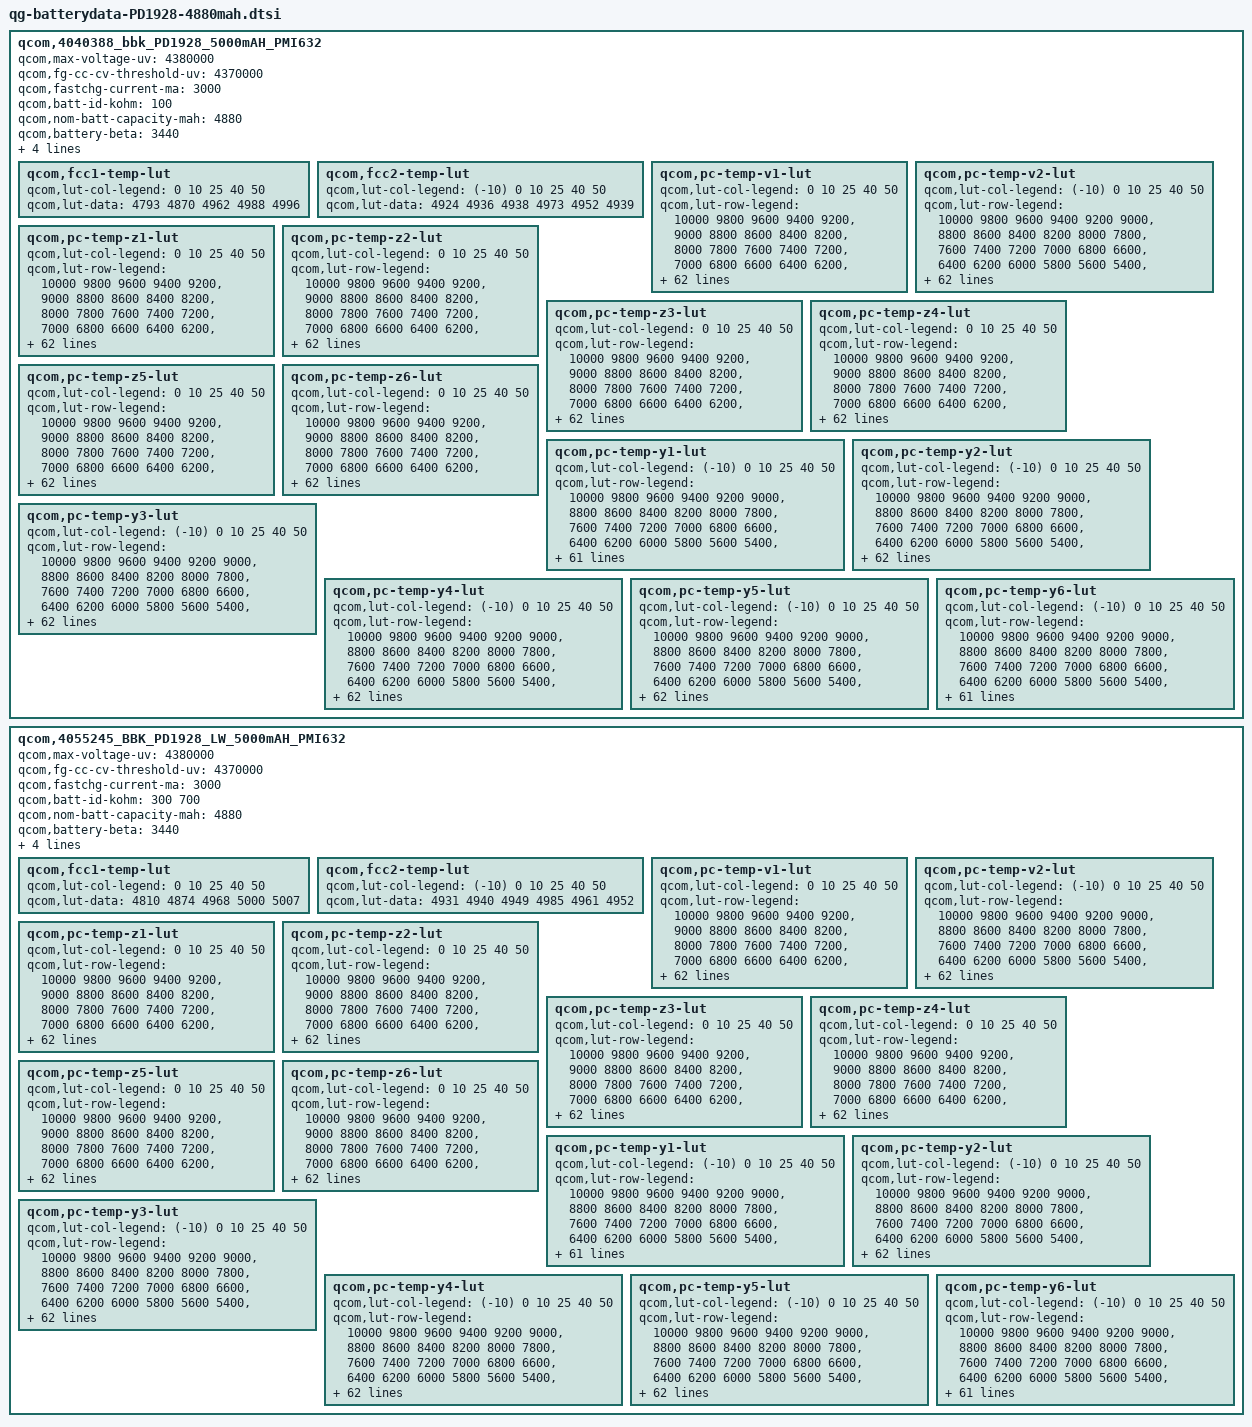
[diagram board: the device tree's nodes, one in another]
/*
 * Copyright (c) 2018, The Linux Foundation. All rights reserved.
 *
 * This program is free software; you can redistribute it and/or modify
 * it under the terms of the GNU General Public License version 2 and
 * only version 2 as published by the Free Software Foundation.
 *
 * This program is distributed in the hope that it will be useful,
 * but WITHOUT ANY WARRANTY; without even the implied warranty of
 * MERCHANTABILITY or FITNESS FOR A PARTICULAR PURPOSE.  See the
 * GNU General Public License for more details.
 */

qcom,4040388_bbk_PD1928_5000mAH_PMI632 {
    /* 4040388_bbk_PD1928_5000mAH_PMI632_averaged_MasterSlave_Jun3th2019 */
    qcom,max-voltage-uv = <4380000>;
    qcom,fg-cc-cv-threshold-uv = <4370000>;
    qcom,fastchg-current-ma = <3000>;
    qcom,batt-id-kohm = <100>;
    qcom,nom-batt-capacity-mah = <4880>;/*min value*/
    qcom,battery-beta = <3440>;
    qcom,battery-therm-kohm = <10>;
    qcom,battery-type = "vivo_PD1928_batterydata:batid(100)";
    qcom,qg-batt-profile-ver = <100>;

	qcom,fcc1-temp-lut {
		qcom,lut-col-legend = <0 10 25 40 50>;
		qcom,lut-data = <4793 4870 4962 4988 4996>;
	};

	qcom,fcc2-temp-lut {
		qcom,lut-col-legend = <(-10) 0 10 25 40 50>;
		qcom,lut-data = <4924 4936 4938 4973 4952 4939>;
	};

	qcom,pc-temp-v1-lut {
		qcom,lut-col-legend = <0 10 25 40 50>;
		qcom,lut-row-legend = <10000 9800 9600 9400 9200>,
			<9000 8800 8600 8400 8200>,
			<8000 7800 7600 7400 7200>,
			<7000 6800 6600 6400 6200>,
			<6000 5800 5600 5400 5200>,
			<5000 4800 4600 4400 4200>,
			<4000 3800 3600 3400 3200>,
			<3000 2800 2600 2400 2200>,
			<2000 1800 1600 1400 1200>,
			<1000 900 800 700 600>,
			<500 400 300 200 100>,
			<0>;
		qcom,lut-data = <43511 43601 43661 43681 43684>,
			<43280 43384 43430 43447 43452>,
			<43030 43152 43198 43214 43222>,
			<42784 42910 42962 42981 42992>,
			<42549 42671 42724 42750 42764>,
			<42320 42434 42490 42520 42536>,
			<42100 42201 42258 42290 42307>,
			<41888 41976 42030 42062 42078>,
			<41683 41758 41804 41836 41854>,
			<41480 41545 41581 41612 41632>,
			<41280 41339 41366 41392 41414>,
			<41084 41139 41162 41178 41198>,
			<40893 40940 40961 40968 40986>,
			<40703 40745 40754 40765 40782>,
			<40492 40547 40543 40566 40583>,
			<40253 40335 40343 40374 40392>,
			<40041 40124 40150 40188 40208>,
			<39890 39952 39971 40011 40032>,
			<39763 39823 39822 39848 39866>,
			<39628 39689 39693 39703 39715>,
			<39484 39494 39537 39543 39551>,
			<39330 39256 39318 39336 39346>,
			<39152 39064 39096 39120 39131>,
			<38948 38920 38929 38946 38955>,
			<38796 38799 38790 38798 38805>,
			<38709 38694 38669 38670 38675>,
			<38641 38603 38564 38559 38561>,
			<38574 38522 38470 38462 38460>,
			<38510 38449 38385 38371 38369>,
			<38451 38383 38308 38288 38285>,
			<38397 38326 38242 38214 38209>,
			<38348 38274 38182 38148 38137>,
			<38304 38227 38131 38089 38072>,
			<38267 38186 38086 38038 38014>,
			<38233 38148 38050 37995 37965>,
			<38202 38114 38012 37950 37912>,
			<38174 38086 37976 37899 37850>,
			<38138 38052 37936 37843 37782>,
			<38073 37994 37877 37776 37707>,
			<37983 37908 37793 37696 37624>,
			<37886 37809 37696 37604 37531>,
			<37774 37691 37587 37495 37420>,
			<37640 37555 37461 37368 37292>,
			<37476 37395 37307 37213 37137>,
			<37348 37254 37170 37079 37008>,
			<37257 37157 37076 36990 36926>,
			<37222 37129 37047 36963 36904>,
			<37195 37107 37028 36945 36883>,
			<37167 37089 37009 36924 36860>,
			<37103 37031 36942 36839 36750>,
			<36844 36751 36646 36524 36421>,
			<36398 36311 36210 36086 35982>,
			<35829 35747 35644 35521 35413>,
			<35061 34980 34876 34754 34639>,
			<33849 33784 33685 33567 33442>,
			<30000 30000 30000 30000 30000>;
	};

	qcom,pc-temp-v2-lut {
		qcom,lut-col-legend = <(-10) 0 10 25 40 50>;
		qcom,lut-row-legend = <10000 9800 9600 9400 9200 9000>,
			<8800 8600 8400 8200 8000 7800>,
			<7600 7400 7200 7000 6800 6600>,
			<6400 6200 6000 5800 5600 5400>,
			<5200 5000 4800 4600 4400 4200>,
			<4000 3800 3600 3400 3200 3000>,
			<2800 2600 2400 2200 2000 1800>,
			<1600 1400 1200 1000 900 800>,
			<700 600 500 400 300 200>,
			<100 0>;
		qcom,lut-data = <43685 43690 43655 43665 43590 43575>,
			<43310 43365 43368 43386 43326 43314>,
			<42966 43063 43097 43120 43070 43062>,
			<42658 42788 42843 42869 42825 42819>,
			<42384 42539 42605 42633 42590 42585>,
			<42123 42299 42375 42401 42359 42355>,
			<41852 42062 42144 42168 42128 42125>,
			<41592 41829 41917 41938 41900 41897>,
			<41386 41601 41695 41713 41675 41673>,
			<41236 41375 41475 41491 41454 41452>,
			<41079 41162 41261 41273 41236 41235>,
			<40871 40983 41060 41061 41022 41022>,
			<40624 40817 40866 40853 40813 40814>,
			<40340 40614 40658 40647 40611 40613>,
			<39973 40347 40430 40441 40413 40416>,
			<39635 40078 40207 40242 40223 40226>,
			<39431 39854 40015 40051 40046 40049>,
			<39279 39650 39838 39868 39876 39879>,
			<39118 39457 39650 39695 39708 39711>,
			<38933 39272 39442 39539 39546 39551>,
			<38752 39096 39238 39373 39376 39382>,
			<38591 38927 39050 39161 39164 39174>,
			<38442 38767 38874 38929 38930 38938>,
			<38330 38623 38720 38752 38748 38752>,
			<38253 38495 38588 38616 38614 38618>,
			<38190 38379 38471 38499 38500 38504>,
			<38131 38270 38365 38394 38395 38397>,
			<38077 38168 38268 38299 38298 38299>,
			<38024 38083 38180 38212 38210 38210>,
			<37975 38016 38104 38135 38129 38127>,
			<37927 37959 38034 38063 38056 38052>,
			<37881 37909 37963 37996 37991 37985>,
			<37836 37865 37893 37935 37933 37926>,
			<37789 37823 37835 37873 37870 37860>,
			<37741 37782 37794 37813 37798 37776>,
			<37689 37741 37755 37751 37720 37680>,
			<37632 37691 37709 37680 37629 37579>,
			<37569 37632 37653 37602 37524 37466>,
			<37499 37565 37589 37527 37430 37365>,
			<37423 37488 37517 37458 37357 37287>,
			<37340 37401 37433 37383 37285 37215>,
			<37248 37303 37335 37292 37195 37125>,
			<37146 37187 37216 37182 37085 37014>,
			<37036 37068 37089 37046 36956 36894>,
			<36917 36944 36964 36934 36846 36782>,
			<36804 36827 36896 36886 36810 36750>,
			<36743 36778 36875 36871 36792 36737>,
			<36679 36731 36844 36847 36774 36713>,
			<36605 36658 36789 36806 36731 36666>,
			<36495 36532 36667 36691 36577 36473>,
			<36272 36273 36335 36376 36191 36091>,
			<35859 35817 35834 35874 35682 35581>,
			<35258 35176 35167 35228 35015 34909>,
			<34398 34310 34232 34308 34068 33957>,
			<32720 32801 32734 33134 32606 32710>,
			<29047 29025 29016 29015 29435 29015>;
	};

	qcom,pc-temp-z1-lut {
		qcom,lut-col-legend = <0 10 25 40 50>;
		qcom,lut-row-legend = <10000 9800 9600 9400 9200>,
			<9000 8800 8600 8400 8200>,
			<8000 7800 7600 7400 7200>,
			<7000 6800 6600 6400 6200>,
			<6000 5800 5600 5400 5200>,
			<5000 4800 4600 4400 4200>,
			<4000 3800 3600 3400 3200>,
			<3000 2800 2600 2400 2200>,
			<2000 1800 1600 1400 1200>,
			<1000 900 800 700 600>,
			<500 400 300 200 100>,
			<0>;
		qcom,lut-data = <13473 12934 12333 12105 12065>,
			<13505 12948 12329 12109 12069>,
			<13490 12937 12325 12110 12070>,
			<13482 12923 12318 12108 12069>,
			<13487 12913 12310 12105 12067>,
			<13498 12906 12305 12102 12066>,
			<13501 12901 12300 12099 12064>,
			<13487 12899 12297 12096 12062>,
			<13473 12901 12295 12094 12061>,
			<13474 12903 12293 12093 12059>,
			<13482 12904 12291 12092 12058>,
			<13485 12905 12289 12091 12058>,
			<13476 12902 12287 12091 12058>,
			<13461 12883 12284 12091 12058>,
			<13447 12869 12281 12090 12057>,
			<13427 12868 12279 12090 12057>,
			<13415 12868 12278 12090 12058>,
			<13424 12869 12276 12089 12059>,
			<13444 12869 12277 12089 12060>,
			<13453 12870 12279 12091 12061>,
			<13455 12875 12282 12092 12062>,
			<13458 12885 12287 12095 12064>,
			<13468 12891 12293 12099 12067>,
			<13487 12894 12298 12101 12070>,
			<13502 12895 12303 12103 12071>,
			<13507 12895 12307 12105 12073>,
			<13509 12894 12311 12108 12076>,
			<13507 12893 12315 12111 12079>,
			<13491 12892 12319 12115 12082>,
			<13479 12890 12323 12118 12084>,
			<13485 12892 12327 12121 12085>,
			<13497 12902 12331 12124 12086>,
			<13501 12909 12334 12126 12088>,
			<13498 12909 12337 12128 12090>,
			<13494 12909 12342 12131 12095>,
			<13495 12911 12346 12135 12099>,
			<13500 12916 12350 12139 12102>,
			<13504 12922 12354 12143 12105>,
			<13508 12927 12358 12145 12108>,
			<13512 12933 12362 12147 12111>,
			<13512 12935 12365 12148 12114>,
			<13506 12927 12369 12150 12115>,
			<13509 12922 12372 12152 12116>,
			<13538 12921 12376 12154 12118>,
			<13527 12932 12375 12157 12118>,
			<13533 12926 12374 12155 12119>,
			<13513 12942 12379 12155 12119>,
			<13496 12921 12378 12155 12117>,
			<13496 12925 12382 12158 12121>,
			<13531 12941 12388 12161 12126>,
			<13532 12950 12392 12168 12130>,
			<13524 12952 12399 12172 12134>,
			<13551 12988 12412 12182 12143>,
			<13623 13009 12427 12193 12154>,
			<13623 13009 12427 12193 12154>,
			<13623 13009 12427 12193 12154>;
	};

	qcom,pc-temp-z2-lut {
		qcom,lut-col-legend = <0 10 25 40 50>;
		qcom,lut-row-legend = <10000 9800 9600 9400 9200>,
			<9000 8800 8600 8400 8200>,
			<8000 7800 7600 7400 7200>,
			<7000 6800 6600 6400 6200>,
			<6000 5800 5600 5400 5200>,
			<5000 4800 4600 4400 4200>,
			<4000 3800 3600 3400 3200>,
			<3000 2800 2600 2400 2200>,
			<2000 1800 1600 1400 1200>,
			<1000 900 800 700 600>,
			<500 400 300 200 100>,
			<0>;
		qcom,lut-data = <11159 10498 10585 10512 10410>,
			<10482 11372 11200 10523 10471>,
			<10366 11255 11527 10525 10506>,
			<10311 10849 11503 10517 10505>,
			<10295 10671 11408 10485 10475>,
			<10286 10671 11335 10471 10460>,
			<10289 10679 11279 10837 10476>,
			<10344 10680 11240 11353 10493>,
			<10407 10678 11231 11485 10499>,
			<10436 10673 11234 11529 10505>,
			<10457 10666 11224 11545 10507>,
			<10474 10661 11198 11158 10508>,
			<10530 10664 11156 10614 10509>,
			<10599 10676 11010 10509 10505>,
			<10619 10686 10739 10480 10489>,
			<10625 10693 10639 10465 10481>,
			<10627 10699 10640 10470 10491>,
			<10604 10697 10642 10480 10505>,
			<10548 10683 10631 10493 10512>,
			<10499 10657 10605 10531 10530>,
			<10454 10587 10597 10552 10540>,
			<10415 10471 10634 10506 10513>,
			<10390 10429 10687 10442 10464>,
			<10370 10447 10816 10435 10426>,
			<10359 10469 11114 10451 10387>,
			<10352 10478 11232 10465 10368>,
			<10347 10482 10972 10473 10389>,
			<10348 10488 10679 10480 10423>,
			<10357 10496 10658 10484 10432>,
			<10368 10507 10689 10496 10428>,
			<10378 10520 10710 10501 10428>,
			<10388 10540 10716 10505 10445>,
			<10400 10557 10721 10515 10472>,
			<10418 10566 10730 10526 10491>,
			<10435 10573 10743 10537 10504>,
			<10445 10580 10761 10554 10522>,
			<10453 10587 10790 10615 10582>,
			<10461 10598 10825 10689 10653>,
			<10471 10687 10856 10703 10663>,
			<10482 10864 10890 10696 10646>,
			<10491 10915 10910 10689 10632>,
			<10499 10743 10911 10684 10603>,
			<10504 10651 10909 10681 10574>,
			<10506 10651 10910 10725 10575>,
			<14177 10700 10901 10685 10547>,
			<12453 10699 10896 10634 10519>,
			<15308 10712 10915 10648 10557>,
			<16014 10710 10884 10699 10597>,
			<13473 10867 10909 10719 10604>,
			<11731 10908 10975 10795 10536>,
			<16052 10789 10901 10486 10351>,
			<13479 10759 10799 10445 10280>,
			<14509 10749 10724 10414 10213>,
			<11040 10689 10652 10289 10143>,
			<11040 10689 10652 10289 10143>,
			<11040 10689 10652 10289 10143>;
	};

	qcom,pc-temp-z3-lut {
		qcom,lut-col-legend = <0 10 25 40 50>;
		qcom,lut-row-legend = <10000 9800 9600 9400 9200>,
			<9000 8800 8600 8400 8200>,
			<8000 7800 7600 7400 7200>,
			<7000 6800 6600 6400 6200>,
			<6000 5800 5600 5400 5200>,
			<5000 4800 4600 4400 4200>,
			<4000 3800 3600 3400 3200>,
			<3000 2800 2600 2400 2200>,
			<2000 1800 1600 1400 1200>,
			<1000 900 800 700 600>,
			<500 400 300 200 100>,
			<0>;
		qcom,lut-data = <19302 19349 19335 19345 19308>,
			<19690 19420 19374 19356 19333>,
			<19726 19479 19397 19362 19349>,
			<19735 19544 19402 19361 19352>,
			<19738 19567 19404 19357 19350>,
			<19744 19558 19403 19355 19349>,
			<19742 19542 19396 19356 19348>,
			<19706 19527 19389 19357 19347>,
			<19669 19511 19389 19357 19344>,
			<19658 19503 19389 19356 19340>,
			<19653 19504 19390 19354 19336>,
			<19649 19506 19390 19348 19334>,
			<19634 19506 19390 19340 19333>,
			<19614 19502 19386 19340 19333>,
			<19610 19497 19377 19341 19334>,
			<19609 19492 19371 19341 19335>,
			<19608 19486 19366 19340 19333>,
			<19605 19482 19363 19339 19331>,
			<19601 19471 19362 19338 19330>,
			<19602 19463 19361 19338 19329>,
			<19624 19484 19362 19338 19329>,
			<19656 19536 19376 19344 19339>,
			<19682 19556 19395 19355 19354>,
			<19708 19556 19404 19360 19357>,
			<19719 19556 19410 19363 19358>,
			<19711 19554 19412 19364 19358>,
			<19697 19547 19407 19364 19357>,
			<19686 19540 19402 19363 19357>,
			<19676 19535 19401 19363 19355>,
			<19669 19529 19401 19362 19349>,
			<19665 19526 19400 19361 19344>,
			<19663 19521 19398 19357 19342>,
			<19659 19518 19396 19352 19341>,
			<19651 19515 19394 19348 19340>,
			<19643 19511 19392 19346 19337>,
			<19641 19509 19390 19344 19334>,
			<19640 19507 19387 19343 19332>,
			<19639 19504 19385 19343 19330>,
			<19638 19494 19382 19342 19330>,
			<19635 19479 19377 19339 19332>,
			<19629 19473 19374 19338 19334>,
			<19609 19482 19373 19337 19335>,
			<19601 19487 19372 19338 19336>,
			<19600 19486 19372 19345 19342>,
			<19313 19464 19360 19343 19344>,
			<19258 19460 19355 19342 19343>,
			<19257 19456 19359 19338 19323>,
			<19257 19454 19355 19325 19322>,
			<19258 19408 19344 19319 19316>,
			<19259 19404 19346 19317 19331>,
			<19257 19434 19357 19340 19342>,
			<19258 19440 19363 19345 19342>,
			<19257 19427 19368 19344 19344>,
			<19259 19420 19382 19350 19350>,
			<19259 19420 19382 19350 19350>,
			<19259 19420 19382 19350 19350>;
	};

	qcom,pc-temp-z4-lut {
		qcom,lut-col-legend = <0 10 25 40 50>;
		qcom,lut-row-legend = <10000 9800 9600 9400 9200>,
			<9000 8800 8600 8400 8200>,
			<8000 7800 7600 7400 7200>,
			<7000 6800 6600 6400 6200>,
			<6000 5800 5600 5400 5200>,
			<5000 4800 4600 4400 4200>,
			<4000 3800 3600 3400 3200>,
			<3000 2800 2600 2400 2200>,
			<2000 1800 1600 1400 1200>,
			<1000 900 800 700 600>,
			<500 400 300 200 100>,
			<0>;
		qcom,lut-data = <15672 15243 14973 14774 14800>,
			<15435 15213 14946 14813 14805>,
			<15425 15147 14921 14835 14807>,
			<15391 15045 14889 14832 14804>,
			<15301 14975 14848 14814 14790>,
			<15180 14934 14826 14797 14778>,
			<15111 14905 14816 14782 14772>,
			<15073 14893 14808 14768 14768>,
			<15048 14887 14798 14761 14763>,
			<15034 14880 14787 14754 14758>,
			<15023 14870 14777 14751 14754>,
			<15017 14860 14766 14754 14750>,
			<15010 14858 14758 14758 14745>,
			<15004 14859 14760 14756 14740>,
			<15003 14859 14767 14746 14734>,
			<15003 14853 14769 14736 14728>,
			<15002 14841 14762 14728 14722>,
			<14980 14833 14751 14720 14715>,
			<14940 14822 14742 14713 14710>,
			<14926 14813 14731 14706 14705>,
			<14931 14862 14731 14704 14702>,
			<14940 14981 14801 14745 14731>,
			<14983 15026 14875 14803 14776>,
			<15095 14993 14872 14811 14784>,
			<15152 14947 14845 14806 14781>,
			<15115 14919 14827 14799 14778>,
			<15052 14896 14820 14791 14772>,
			<15015 14880 14813 14781 14765>,
			<14992 14869 14805 14773 14759>,
			<14974 14860 14794 14765 14754>,
			<14960 14852 14785 14758 14749>,
			<14949 14845 14777 14751 14743>,
			<14942 14840 14771 14744 14735>,
			<14938 14837 14764 14737 14727>,
			<14934 14834 14757 14729 14718>,
			<14928 14830 14754 14726 14713>,
			<14920 14823 14756 14735 14724>,
			<14915 14818 14759 14749 14741>,
			<14919 14821 14764 14751 14744>,
			<14923 14826 14772 14750 14739>,
			<14924 14828 14776 14748 14734>,
			<14922 14819 14765 14740 14727>,
			<14918 14812 14756 14734 14722>,
			<14910 14810 14758 14737 14733>,
			<15151 14806 14761 14736 14730>,
			<15178 14789 14753 14720 14705>,
			<15168 14777 14735 14712 14703>,
			<15156 14767 14716 14700 14684>,
			<15143 14797 14702 14680 14665>,
			<15140 14797 14705 14690 14673>,
			<15160 14787 14720 14698 14688>,
			<15169 14782 14717 14696 14691>,
			<15177 14797 14713 14697 14690>,
			<15186 14809 14701 14693 14684>,
			<15186 14809 14701 14693 14684>,
			<15186 14809 14701 14693 14684>;
	};

	qcom,pc-temp-z5-lut {
		qcom,lut-col-legend = <0 10 25 40 50>;
		qcom,lut-row-legend = <10000 9800 9600 9400 9200>,
			<9000 8800 8600 8400 8200>,
			<8000 7800 7600 7400 7200>,
			<7000 6800 6600 6400 6200>,
			<6000 5800 5600 5400 5200>,
			<5000 4800 4600 4400 4200>,
			<4000 3800 3600 3400 3200>,
			<3000 2800 2600 2400 2200>,
			<2000 1800 1600 1400 1200>,
			<1000 900 800 700 600>,
			<500 400 300 200 100>,
			<0>;
		qcom,lut-data = <11012 11750 13684 15166 13795>,
			<13792 12827 15094 16546 16147>,
			<14646 14061 16156 17467 17794>,
			<15232 15509 16915 17714 18357>,
			<15780 16382 17572 17778 18643>,
			<16300 16872 17712 17835 18788>,
			<16423 17174 17406 17956 18849>,
			<15786 17052 17132 18117 18884>,
			<15177 16500 17282 18305 18775>,
			<15259 16191 17700 18540 18217>,
			<15501 16368 18003 18640 17866>,
			<15664 16631 18308 18118 17893>,
			<15451 16687 18499 17424 17962>,
			<15101 16599 18040 17341 18115>,
			<15030 16472 16956 17440 18534>,
			<15029 16370 16566 17603 18913>,
			<15039 16308 16792 18101 19153>,
			<15248 16294 17123 18842 19412>,
			<15811 16311 17515 19496 19792>,
			<16660 16418 18071 20179 20416>,
			<18772 17907 18262 20474 20752>,
			<20671 21182 17936 19039 19663>,
			<20923 22380 17538 17058 17995>,
			<20982 20986 17440 16772 17631>,
			<20993 19466 17492 16927 17594>,
			<20089 19411 17536 17144 17591>,
			<18793 19780 17783 17499 17964>,
			<18539 20131 18172 17964 18518>,
			<18680 20513 18601 18442 18554>,
			<18883 20868 19323 19057 18213>,
			<19323 21002 20055 19353 17995>,
			<20011 21297 20737 19325 18289>,
			<20295 21523 21433 19286 18904>,
			<20246 21691 22210 19452 19584>,
			<20184 21928 23103 20276 20530>,
			<20331 22031 23598 20866 21031>,
			<20746 22102 23714 20987 20386>,
			<21064 22101 23674 21015 19394>,
			<21234 21346 23168 20731 19262>,
			<21363 19765 21669 19631 19572>,
			<21096 19195 20726 18884 19847>,
			<19429 20410 20590 18786 19974>,
			<18820 21079 20443 18799 20090>,
			<18849 20989 19952 19303 20449>,
			<12622 18960 17908 18784 20512>,
			<11261 18782 17217 18155 20261>,
			<11254 18675 18132 17905 16508>,
			<11246 18949 18364 16523 17049>,
			<11250 15521 17831 17331 18345>,
			<11259 15186 17884 16299 20328>,
			<11247 16548 16853 16980 19017>,
			<11197 16616 17023 17213 17825>,
			<11135 15537 17228 16403 17188>,
			<11074 14953 18707 16547 17165>,
			<11074 14953 18707 16547 17165>,
			<11074 14953 18707 16547 17165>;
	};

	qcom,pc-temp-z6-lut {
		qcom,lut-col-legend = <0 10 25 40 50>;
		qcom,lut-row-legend = <10000 9800 9600 9400 9200>,
			<9000 8800 8600 8400 8200>,
			<8000 7800 7600 7400 7200>,
			<7000 6800 6600 6400 6200>,
			<6000 5800 5600 5400 5200>,
			<5000 4800 4600 4400 4200>,
			<4000 3800 3600 3400 3200>,
			<3000 2800 2600 2400 2200>,
			<2000 1800 1600 1400 1200>,
			<1000 900 800 700 600>,
			<500 400 300 200 100>,
			<0>;
		qcom,lut-data = <15743 15190 14843 14719 14706>,
			<15789 15199 14850 14743 14723>,
			<15757 15190 14851 14756 14732>,
			<15713 15162 14842 14755 14732>,
			<15653 15134 14823 14744 14725>,
			<15578 15107 14809 14735 14718>,
			<15521 15081 14800 14729 14715>,
			<15476 15063 14792 14725 14713>,
			<15444 15049 14786 14721 14709>,
			<15430 15040 14782 14717 14704>,
			<15423 15034 14777 14714 14700>,
			<15413 15030 14772 14712 14697>,
			<15395 15024 14768 14709 14695>,
			<15376 15019 14765 14706 14692>,
			<15368 15013 14763 14702 14690>,
			<15365 15006 14761 14699 14687>,
			<15362 14999 14755 14694 14684>,
			<15351 14991 14748 14690 14680>,
			<15337 14982 14743 14687 14677>,
			<15333 14976 14739 14684 14674>,
			<15348 15009 14740 14683 14673>,
			<15373 15089 14780 14706 14693>,
			<15414 15120 14823 14738 14722>,
			<15479 15109 14825 14743 14727>,
			<15511 15092 14819 14743 14726>,
			<15493 15080 14814 14742 14725>,
			<15464 15068 14808 14739 14723>,
			<15446 15060 14803 14734 14720>,
			<15434 15053 14799 14730 14716>,
			<15426 15049 14795 14727 14711>,
			<15422 15045 14791 14723 14706>,
			<15420 15042 14787 14718 14702>,
			<15418 15040 14784 14713 14699>,
			<15416 15039 14781 14708 14694>,
			<15414 15039 14777 14703 14689>,
			<15414 15038 14775 14701 14686>,
			<15417 15038 14776 14705 14689>,
			<15419 15037 14777 14711 14696>,
			<15426 15036 14778 14712 14697>,
			<15435 15035 14780 14711 14697>,
			<15436 15035 14781 14709 14696>,
			<15433 15038 14776 14706 14694>,
			<15434 15040 14772 14703 14692>,
			<15440 15042 14774 14709 14701>,
			<15417 15033 14770 14708 14700>,
			<15404 15027 14764 14700 14689>,
			<15402 15021 14758 14695 14679>,
			<15400 15015 14747 14683 14669>,
			<15398 15008 14737 14672 14658>,
			<15404 15009 14740 14675 14670>,
			<15423 15026 14754 14692 14685>,
			<15440 15032 14758 14696 14687>,
			<15463 15041 14762 14698 14690>,
			<15496 15056 14768 14703 14694>,
			<15496 15056 14768 14703 14694>,
			<15496 15056 14768 14703 14694>;
	};

	qcom,pc-temp-y1-lut {
		qcom,lut-col-legend = <(-10) 0 10 25 40 50>;
		qcom,lut-row-legend = <10000 9800 9600 9400 9200 9000>,
			<8800 8600 8400 8200 8000 7800>,
			<7600 7400 7200 7000 6800 6600>,
			<6400 6200 6000 5800 5600 5400>,
			<5200 5000 4800 4600 4400 4200>,
			<4000 3800 3600 3400 3200 3000>,
			<2800 2600 2400 2200 2000 1800>,
			<1600 1400 1200 1000 900 800>,
			<700 600 500 400 300 200>,
			<100 0>;
		qcom,lut-data = <6758 6304 5977 5600 5463 5428>,
			<6762 6285 5967 5594 5462 5428>,
			<6765 6268 5957 5589 5460 5427>,
			<6765 6254 5947 5584 5457 5427>,
			<6765 6243 5939 5579 5455 5426>,
			<6763 6237 5933 5575 5453 5426>,
			<6758 6236 5930 5572 5452 5425>,
			<6750 6238 5927 5570 5450 5425>,
			<6747 6238 5924 5567 5449 5424>,
			<6746 6238 5919 5564 5447 5423>,
			<6746 6238 5914 5561 5445 5423>,
			<6747 6233 5909 5560 5443 5422>,
			<6749 6225 5904 5558 5442 5422>,
			<6751 6224 5902 5557 5442 5422>,
			<6753 6231 5901 5556 5444 5422>,
			<6754 6239 5900 5555 5445 5422>,
			<6753 6238 5902 5556 5444 5422>,
			<6748 6235 5907 5557 5443 5421>,
			<6745 6234 5908 5558 5443 5421>,
			<6739 6238 5909 5558 5443 5421>,
			<6733 6241 5909 5559 5443 5422>,
			<6733 6238 5909 5559 5443 5422>,
			<6737 6231 5907 5560 5443 5423>,
			<6737 6228 5906 5561 5443 5423>,
			<6735 6233 5909 5564 5445 5425>,
			<6731 6238 5912 5567 5448 5426>,
			<6724 6241 5914 5569 5449 5428>,
			<6715 6244 5916 5571 5450 5429>,
			<6709 6245 5918 5574 5451 5430>,
			<6707 6246 5920 5578 5454 5432>,
			<6706 6246 5922 5582 5458 5434>,
			<6707 6245 5923 5586 5461 5436>,
			<6715 6243 5923 5591 5463 5438>,
			<6720 6242 5924 5594 5465 5439>,
			<6716 6246 5926 5596 5467 5441>,
			<6709 6252 5928 5598 5469 5443>,
			<6703 6249 5929 5601 5471 5444>,
			<6697 6234 5930 5604 5472 5446>,
			<6693 6226 5931 5606 5474 5447>,
			<6694 6229 5935 5607 5475 5448>,
			<6696 6236 5939 5608 5476 5450>,
			<6699 6242 5938 5610 5478 5452>,
			<6701 6250 5931 5612 5479 5454>,
			<6699 6247 5935 5614 5481 5455>,
			<6682 6232 5953 5617 5483 5457>,
			<6677 6231 5947 5622 5486 5459>,
			<6677 6234 5944 5624 5486 5457>,
			<6691 6225 5943 5625 5484 5459>,
			<6683 6239 5953 5626 5484 5458>,
			<6671 6231 5949 5628 5486 5460>,
			<6680 6249 5953 5631 5490 5462>,
			<6695 6252 5968 5637 5495 5467>,
			<6713 6261 5987 5647 5503 5472>,
			<6737 6278 5999 5662 5510 5482>,
			<6737 6278 5999 5662 5510 5482>,
			<6737 6278 5999 5662 5510 5482>;
	};

	qcom,pc-temp-y2-lut {
		qcom,lut-col-legend = <(-10) 0 10 25 40 50>;
		qcom,lut-row-legend = <10000 9800 9600 9400 9200 9000>,
			<8800 8600 8400 8200 8000 7800>,
			<7600 7400 7200 7000 6800 6600>,
			<6400 6200 6000 5800 5600 5400>,
			<5200 5000 4800 4600 4400 4200>,
			<4000 3800 3600 3400 3200 3000>,
			<2800 2600 2400 2200 2000 1800>,
			<1600 1400 1200 1000 900 800>,
			<700 600 500 400 300 200>,
			<100 0>;
		qcom,lut-data = <10170 10613 11052 11312 11370 11212>,
			<10165 10617 11039 11314 11330 11218>,
			<10162 10621 11021 11304 11268 11209>,
			<10162 10625 11003 11287 11200 11190>,
			<10164 10629 10987 11269 11142 11166>,
			<10169 10632 10977 11254 11112 11142>,
			<10249 10635 10974 11223 11106 11109>,
			<10390 10638 10972 11183 11102 11071>,
			<10425 10641 10967 11175 11095 11057>,
			<10401 10642 10955 11182 11071 11058>,
			<10382 10645 10946 11186 11055 11061>,
			<10424 10685 10944 11172 11072 11058>,
			<10516 10768 10943 11144 11104 11051>,
			<10512 10820 10947 11130 11107 11051>,
			<10112 10848 10982 11119 11052 11069>,
			<9730 10871 11025 11115 11007 11084>,
			<9697 10889 11054 11155 11012 11084>,
			<9690 10906 11079 11235 11031 11084>,
			<9684 10926 11101 11295 11066 11085>,
			<9678 10956 11118 11350 11177 11113>,
			<9673 10990 11137 11386 11268 11140>,
			<9670 11025 11178 11390 11256 11167>,
			<9669 11063 11247 11387 11219 11234>,
			<9667 11096 11319 11394 11210 11265>,
			<9665 11124 11404 11422 11253 11269>,
			<9663 11150 11481 11456 11302 11270>,
			<9662 11176 11526 11492 11321 11278>,
			<9661 11202 11562 11529 11338 11304>,
			<9660 11216 11572 11550 11355 11326>,
			<9659 11221 11508 11568 11394 11354>,
			<9658 11224 11434 11583 11436 11386>,
			<9657 11117 11443 11600 11463 11411>,
			<9657 10720 11508 11626 11486 11435>,
			<9656 10496 11541 11632 11497 11444>,
			<9656 10516 11488 11615 11499 11422>,
			<9655 10540 11407 11594 11498 11391>,
			<9655 10434 11367 11585 11488 11380>,
			<9654 10088 11344 11584 11459 11378>,
			<9654 9834 11320 11587 11436 11373>,
			<9654 9758 11292 11611 11404 11359>,
			<9654 9711 11260 11629 11374 11336>,
			<9654 9692 11215 11609 11357 11297>,
			<9654 9683 11148 11578 11324 11229>,
			<9654 9675 11070 11575 11322 11203>,
			<9653 9669 10975 11565 11324 11194>,
			<9653 9665 10860 11464 11219 11082>,
			<9653 9665 10872 11449 11189 11009>,
			<9653 9664 10830 11446 11133 11002>,
			<9653 9663 10778 11404 11155 10997>,
			<9653 9661 10709 11348 11125 10990>,
			<9653 9659 10607 11316 11034 10893>,
			<9652 9657 10510 11271 10997 10842>,
			<9652 9655 10387 11159 10880 10762>,
			<9650 9654 10225 11014 10770 10620>,
			<9650 9654 10225 11014 10770 10620>,
			<9650 9654 10225 11014 10770 10620>;
	};

	qcom,pc-temp-y3-lut {
		qcom,lut-col-legend = <(-10) 0 10 25 40 50>;
		qcom,lut-row-legend = <10000 9800 9600 9400 9200 9000>,
			<8800 8600 8400 8200 8000 7800>,
			<7600 7400 7200 7000 6800 6600>,
			<6400 6200 6000 5800 5600 5400>,
			<5200 5000 4800 4600 4400 4200>,
			<4000 3800 3600 3400 3200 3000>,
			<2800 2600 2400 2200 2000 1800>,
			<1600 1400 1200 1000 900 800>,
			<700 600 500 400 300 200>,
			<100 0>;
		qcom,lut-data = <13928 13404 13324 13277 13279 13272>,
			<13848 13408 13325 13277 13277 13273>,
			<13789 13413 13325 13278 13276 13273>,
			<13748 13417 13326 13278 13275 13274>,
			<13724 13421 13326 13278 13275 13275>,
			<13716 13423 13326 13278 13275 13275>,
			<13733 13422 13326 13278 13275 13275>,
			<13765 13422 13326 13278 13276 13274>,
			<13756 13421 13327 13279 13276 13274>,
			<13619 13420 13330 13283 13277 13275>,
			<13504 13420 13332 13287 13277 13276>,
			<13527 13421 13332 13287 13277 13276>,
			<13584 13422 13331 13287 13277 13276>,
			<13597 13422 13331 13287 13278 13276>,
			<13530 13416 13335 13287 13280 13277>,
			<13467 13407 13339 13286 13283 13279>,
			<13468 13400 13339 13288 13282 13279>,
			<13477 13393 13339 13292 13282 13280>,
			<13481 13386 13338 13294 13282 13281>,
			<13477 13379 13333 13296 13284 13283>,
			<13471 13372 13327 13297 13287 13284>,
			<13458 13366 13322 13294 13284 13282>,
			<13433 13360 13317 13288 13278 13276>,
			<13424 13355 13312 13284 13276 13273>,
			<13445 13349 13306 13282 13276 13273>,
			<13480 13343 13302 13281 13276 13274>,
			<13511 13338 13299 13281 13276 13274>,
			<13542 13333 13298 13281 13275 13273>,
			<13577 13329 13297 13281 13275 13273>,
			<13616 13326 13303 13282 13275 13273>,
			<13660 13323 13310 13284 13275 13273>,
			<13710 13317 13309 13284 13275 13274>,
			<13766 13303 13303 13285 13276 13275>,
			<13828 13296 13299 13285 13277 13275>,
			<13895 13307 13304 13285 13277 13274>,
			<13970 13323 13309 13285 13277 13274>,
			<14052 13330 13310 13283 13277 13273>,
			<14143 13332 13310 13281 13276 13273>,
			<14242 13333 13310 13279 13275 13273>,
			<14350 13336 13310 13279 13275 13274>,
			<14467 13341 13310 13279 13276 13275>,
			<14587 13347 13310 13279 13276 13276>,
			<14713 13360 13312 13280 13276 13276>,
			<14832 13388 13314 13280 13276 13276>,
			<14942 13456 13318 13280 13276 13275>,
			<15055 13539 13325 13283 13278 13279>,
			<15022 13547 13331 13287 13279 13283>,
			<15057 13603 13338 13289 13286 13283>,
			<15173 13667 13345 13293 13289 13286>,
			<15298 13743 13356 13295 13286 13281>,
			<15449 13822 13356 13293 13283 13281>,
			<15654 13965 13368 13293 13283 13282>,
			<16230 14234 13390 13297 13288 13285>,
			<17645 14793 13447 13304 13292 13290>,
			<17645 14793 13447 13304 13292 13290>,
			<17645 14793 13447 13304 13292 13290>;
	};

	qcom,pc-temp-y4-lut {
		qcom,lut-col-legend = <(-10) 0 10 25 40 50>;
		qcom,lut-row-legend = <10000 9800 9600 9400 9200 9000>,
			<8800 8600 8400 8200 8000 7800>,
			<7600 7400 7200 7000 6800 6600>,
			<6400 6200 6000 5800 5600 5400>,
			<5200 5000 4800 4600 4400 4200>,
			<4000 3800 3600 3400 3200 3000>,
			<2800 2600 2400 2200 2000 1800>,
			<1600 1400 1200 1000 900 800>,
			<700 600 500 400 300 200>,
			<100 0>;
		qcom,lut-data = <17015 16839 16606 16491 16463 16470>,
			<17397 16845 16603 16490 16464 16467>,
			<17637 16856 16601 16490 16465 16465>,
			<17768 16868 16600 16491 16466 16463>,
			<17822 16878 16599 16492 16467 16463>,
			<17834 16884 16599 16494 16468 16463>,
			<17745 16885 16600 16498 16469 16464>,
			<17583 16885 16601 16503 16471 16467>,
			<17593 16885 16603 16505 16473 16469>,
			<18036 16883 16607 16505 16476 16470>,
			<18404 16881 16614 16506 16480 16471>,
			<18300 16946 16624 16510 16484 16474>,
			<18014 17077 16641 16520 16489 16479>,
			<17789 17114 16660 16530 16494 16482>,
			<17616 17076 16685 16543 16498 16485>,
			<17485 17022 16712 16556 16503 16488>,
			<17418 16972 16741 16566 16511 16493>,
			<17375 16918 16771 16576 16523 16502>,
			<17312 16869 16776 16593 16538 16513>,
			<17185 16825 16718 16625 16560 16533>,
			<17055 16784 16646 16646 16576 16548>,
			<16979 16745 16599 16605 16554 16534>,
			<16921 16708 16561 16521 16501 16493>,
			<16892 16683 16547 16490 16477 16474>,
			<16879 16670 16546 16482 16471 16470>,
			<16872 16659 16545 16479 16468 16468>,
			<16871 16640 16546 16480 16469 16468>,
			<16874 16615 16549 16482 16470 16469>,
			<16877 16606 16550 16485 16473 16470>,
			<16883 16608 16545 16490 16478 16473>,
			<16891 16613 16539 16497 16484 16479>,
			<16896 16628 16538 16505 16493 16487>,
			<16901 16668 16539 16513 16505 16498>,
			<16906 16691 16539 16516 16509 16502>,
			<16912 16688 16541 16514 16505 16496>,
			<16919 16684 16543 16510 16499 16485>,
			<16928 16691 16544 16500 16489 16476>,
			<16939 16715 16544 16484 16472 16468>,
			<16952 16738 16545 16479 16465 16464>,
			<16969 16752 16548 16484 16470 16467>,
			<16989 16766 16554 16489 16475 16472>,
			<17014 16781 16561 16490 16476 16473>,
			<17046 16798 16572 16490 16475 16473>,
			<17090 16824 16581 16486 16468 16466>,
			<17156 16872 16590 16484 16456 16449>,
			<17263 16996 16628 16496 16476 16469>,
			<17230 17001 16643 16502 16488 16494>,
			<17252 17055 16683 16518 16516 16527>,
			<17340 17150 16743 16551 16548 16563>,
			<17422 17261 16807 16554 16525 16495>,
			<17435 17312 16763 16519 16476 16474>,
			<17418 17346 16781 16512 16482 16476>,
			<17585 17506 16843 16534 16492 16482>,
			<18518 17853 16960 16584 16529 16523>,
			<18518 17853 16960 16584 16529 16523>,
			<18518 17853 16960 16584 16529 16523>;
	};

	qcom,pc-temp-y5-lut {
		qcom,lut-col-legend = <(-10) 0 10 25 40 50>;
		qcom,lut-row-legend = <10000 9800 9600 9400 9200 9000>,
			<8800 8600 8400 8200 8000 7800>,
			<7600 7400 7200 7000 6800 6600>,
			<6400 6200 6000 5800 5600 5400>,
			<5200 5000 4800 4600 4400 4200>,
			<4000 3800 3600 3400 3200 3000>,
			<2800 2600 2400 2200 2000 1800>,
			<1600 1400 1200 1000 900 800>,
			<700 600 500 400 300 200>,
			<100 0>;
		qcom,lut-data = <12056 12364 14371 13689 17966 16350>,
			<11705 12827 14409 13628 17330 16387>,
			<11555 13356 14410 13531 16605 16405>,
			<11559 13857 14384 13411 15901 16406>,
			<11670 14235 14338 13277 15325 16390>,
			<11838 14395 14281 13142 14988 16360>,
			<12199 14340 14204 12961 14879 15970>,
			<12662 14215 14107 12785 14839 15298>,
			<12716 14100 14041 12891 14767 15085>,
			<12214 13975 14158 13737 14567 15132>,
			<11796 13828 14219 14339 14328 15156>,
			<13102 13606 13914 14178 14063 14833>,
			<15928 13358 13443 13823 13803 14270>,
			<16627 13408 13343 13506 13791 14123>,
			<13981 14589 13728 13127 14206 14295>,
			<11494 15674 14298 12908 14549 14483>,
			<11611 15774 14953 13202 14405 14553>,
			<12311 15804 15761 13928 14090 14603>,
			<12816 15870 16377 14745 14077 14733>,
			<13142 16109 16897 15874 14931 15328>,
			<13342 16318 17210 16723 15726 15862>,
			<12930 16306 17056 17042 15788 15791>,
			<11633 16215 16514 17260 15768 15524>,
			<11034 16089 15940 17212 15866 15448>,
			<11081 15819 14998 16440 16651 16039>,
			<11137 15485 14128 15768 17374 16670>,
			<11141 15224 13874 15679 17160 16621>,
			<11130 14979 13720 15633 16451 16278>,
			<11114 14686 13720 15698 15960 15980>,
			<11077 14205 15422 16421 15666 15637>,
			<11040 13684 17432 17201 15494 15345>,
			<11053 13243 17223 17517 15632 15433>,
			<11154 12655 15659 17736 16166 15876>,
			<11261 12391 14858 18033 16766 16202>,
			<11346 12862 16025 18535 17613 16358>,
			<11419 13517 17544 18882 18299 16488>,
			<11453 13485 17700 18288 18219 16597>,
			<11445 12669 17374 16806 17688 16785>,
			<11433 12091 17030 15988 17168 16957>,
			<11433 11969 16534 15544 16676 17102>,
			<11436 11838 15906 15286 16268 17199>,
			<11444 11696 15503 15237 16087 17138>,
			<11476 11536 15228 15175 15938 16968>,
			<11476 11546 15089 15333 16376 17101>,
			<11417 11717 15162 15153 17203 17625>,
			<11433 11699 14826 15271 15096 16858>,
			<11441 11777 15562 16083 15092 17427>,
			<11493 12226 15623 15739 16819 16125>,
			<11622 12502 15425 16059 16795 15860>,
			<11897 12806 15560 16528 16002 15500>,
			<11877 12827 15055 16681 16246 16128>,
			<11545 12373 14960 16704 16048 16071>,
			<10889 11498 14369 17103 17845 16267>,
			<9946 10852 13690 17640 18053 18545>,
			<9946 10852 13690 17640 18053 18545>,
			<9946 10852 13690 17640 18053 18545>;
	};

	qcom,pc-temp-y6-lut {
		qcom,lut-col-legend = <(-10) 0 10 25 40 50>;
		qcom,lut-row-legend = <10000 9800 9600 9400 9200 9000>,
			<8800 8600 8400 8200 8000 7800>,
			<7600 7400 7200 7000 6800 6600>,
			<6400 6200 6000 5800 5600 5400>,
			<5200 5000 4800 4600 4400 4200>,
			<4000 3800 3600 3400 3200 3000>,
			<2800 2600 2400 2200 2000 1800>,
			<1600 1400 1200 1000 900 800>,
			<700 600 500 400 300 200>,
			<100 0>;
		qcom,lut-data = <6423 5542 5234 5069 5046 5041>,
			<6418 5539 5229 5069 5046 5041>,
			<6408 5536 5225 5068 5046 5041>,
			<6395 5531 5221 5068 5046 5041>,
			<6379 5526 5217 5068 5046 5042>,
			<6361 5520 5213 5069 5046 5042>,
			<6333 5512 5210 5069 5046 5042>,
			<6305 5505 5207 5070 5047 5043>,
			<6301 5497 5206 5072 5048 5043>,
			<6329 5489 5206 5074 5049 5044>,
			<6353 5485 5207 5077 5050 5045>,
			<6342 5500 5208 5079 5052 5046>,
			<6309 5531 5211 5081 5053 5047>,
			<6261 5539 5215 5084 5055 5048>,
			<6154 5522 5223 5087 5057 5050>,
			<6067 5499 5232 5090 5061 5052>,
			<6061 5480 5240 5095 5063 5054>,
			<6061 5462 5248 5100 5066 5057>,
			<6058 5444 5249 5106 5070 5061>,
			<6037 5427 5229 5117 5078 5067>,
			<6013 5412 5203 5123 5084 5073>,
			<6005 5398 5187 5109 5076 5067>,
			<6001 5386 5173 5081 5055 5050>,
			<6001 5379 5166 5069 5047 5043>,
			<6025 5376 5162 5065 5046 5042>,
			<6067 5373 5160 5064 5045 5041>,
			<6102 5371 5160 5064 5045 5041>,
			<6137 5368 5161 5065 5045 5042>,
			<6173 5367 5162 5066 5046 5042>,
			<6212 5373 5167 5069 5047 5043>,
			<6253 5383 5172 5073 5049 5045>,
			<6297 5394 5172 5076 5053 5048>,
			<6345 5409 5170 5079 5057 5052>,
			<6396 5425 5170 5080 5059 5053>,
			<6451 5444 5175 5080 5058 5051>,
			<6510 5465 5182 5079 5056 5048>,
			<6574 5486 5186 5076 5053 5045>,
			<6643 5508 5188 5070 5048 5043>,
			<6719 5533 5191 5068 5046 5042>,
			<6803 5563 5195 5069 5047 5043>,
			<6895 5599 5200 5071 5049 5046>,
			<6991 5642 5206 5072 5050 5047>,
			<7093 5694 5216 5073 5050 5047>,
			<7196 5763 5227 5072 5048 5045>,
			<7298 5857 5241 5072 5045 5040>,
			<7412 5982 5269 5078 5052 5049>,
			<7379 5989 5280 5084 5057 5058>,
			<7412 6050 5303 5090 5070 5069>,
			<7522 6137 5335 5102 5081 5081>,
			<7639 6238 5374 5105 5073 5058>,
			<7760 6338 5373 5094 5056 5053>,
			<7907 6482 5411 5093 5060 5055>,
			<8415 6752 5488 5104 5067 5059>,
			<9768 7279 5623 5126 5082 5076>,
			<9768 7279 5623 5126 5082 5076>,
			<9768 7279 5623 5126 5082 5076>;
	};

};

qcom,4055245_BBK_PD1928_LW_5000mAH_PMI632 {
    /* 4055245_BBK_PD1928(TD1901)_LW_5000mAH_PMI632_averaged_MasterSlave_Jun18th2019 */
    qcom,max-voltage-uv = <4380000>;
    qcom,fg-cc-cv-threshold-uv = <4370000>;
    qcom,fastchg-current-ma = <3000>;
    qcom,batt-id-kohm = <300 700>;
    qcom,nom-batt-capacity-mah = <4880>;/*min value*/
    qcom,battery-beta = <3440>;
    qcom,battery-therm-kohm = <10>;
    qcom,battery-type = "vivo_PD1928_batterydata:batid(300)";
    qcom,qg-batt-profile-ver = <100>;

	qcom,fcc1-temp-lut {
		qcom,lut-col-legend = <0 10 25 40 50>;
		qcom,lut-data = <4810 4874 4968 5000 5007>;
	};

	qcom,fcc2-temp-lut {
		qcom,lut-col-legend = <(-10) 0 10 25 40 50>;
		qcom,lut-data = <4931 4940 4949 4985 4961 4952>;
	};

	qcom,pc-temp-v1-lut {
		qcom,lut-col-legend = <0 10 25 40 50>;
		qcom,lut-row-legend = <10000 9800 9600 9400 9200>,
			<9000 8800 8600 8400 8200>,
			<8000 7800 7600 7400 7200>,
			<7000 6800 6600 6400 6200>,
			<6000 5800 5600 5400 5200>,
			<5000 4800 4600 4400 4200>,
			<4000 3800 3600 3400 3200>,
			<3000 2800 2600 2400 2200>,
			<2000 1800 1600 1400 1200>,
			<1000 900 800 700 600>,
			<500 400 300 200 100>,
			<0>;
		qcom,lut-data = <43536 43616 43668 43686 43686>,
			<43296 43378 43441 43481 43478>,
			<43047 43137 43209 43249 43254>,
			<42801 42895 42972 43017 43028>,
			<42567 42657 42731 42781 42797>,
			<42340 42424 42492 42543 42563>,
			<42121 42196 42257 42307 42329>,
			<41908 41975 42025 42072 42095>,
			<41703 41758 41799 41842 41867>,
			<41506 41548 41579 41617 41642>,
			<41320 41351 41367 41395 41420>,
			<41125 41157 41172 41178 41202>,
			<40908 40952 40973 40964 40985>,
			<40675 40736 40745 40754 40777>,
			<40435 40513 40497 40543 40573>,
			<40162 40263 40280 40344 40378>,
			<39933 40010 40096 40162 40191>,
			<39807 39844 39931 39991 40012>,
			<39719 39752 39786 39828 39842>,
			<39616 39658 39657 39678 39687>,
			<39482 39478 39501 39514 39520>,
			<39329 39220 39272 39300 39310>,
			<39153 39017 39036 39071 39085>,
			<38942 38877 38867 38892 38904>,
			<38777 38761 38730 38744 38754>,
			<38688 38661 38613 38617 38624>,
			<38622 38573 38511 38507 38511>,
			<38559 38496 38422 38409 38411>,
			<38501 38425 38343 38320 38320>,
			<38449 38361 38272 38239 38235>,
			<38402 38307 38211 38168 38160>,
			<38358 38259 38156 38105 38090>,
			<38319 38217 38107 38050 38026>,
			<38285 38180 38066 38003 37971>,
			<38253 38148 38032 37964 37925>,
			<38224 38118 37997 37923 37877>,
			<38199 38094 37963 37874 37817>,
			<38165 38063 37924 37818 37749>,
			<38099 38004 37866 37750 37675>,
			<38000 37905 37777 37668 37594>,
			<37889 37796 37674 37572 37502>,
			<37756 37671 37557 37457 37394>,
			<37608 37530 37423 37323 37264>,
			<37442 37366 37267 37163 37077>,
			<37303 37232 37138 37041 36968>,
			<37216 37145 37057 36967 36899>,
			<37191 37120 37032 36944 36879>,
			<37169 37107 37014 36930 36870>,
			<37148 37085 37001 36911 36844>,
			<37089 37030 36934 36824 36727>,
			<36812 36753 36625 36500 36428>,
			<36362 36306 36181 36050 35958>,
			<35780 35732 35601 35468 35370>,
			<34991 34951 34809 34674 34586>,
			<33745 33732 33579 33443 33342>,
			<30000 30000 30000 30000 30000>;
	};

	qcom,pc-temp-v2-lut {
		qcom,lut-col-legend = <(-10) 0 10 25 40 50>;
		qcom,lut-row-legend = <10000 9800 9600 9400 9200 9000>,
			<8800 8600 8400 8200 8000 7800>,
			<7600 7400 7200 7000 6800 6600>,
			<6400 6200 6000 5800 5600 5400>,
			<5200 5000 4800 4600 4400 4200>,
			<4000 3800 3600 3400 3200 3000>,
			<2800 2600 2400 2200 2000 1800>,
			<1600 1400 1200 1000 900 800>,
			<700 600 500 400 300 200>,
			<100 0>;
		qcom,lut-data = <43690 43690 43680 43660 43590 43585>,
			<43317 43370 43390 43400 43339 43339>,
			<42976 43072 43117 43147 43092 43095>,
			<42670 42798 42860 42900 42849 42854>,
			<42397 42548 42620 42659 42612 42615>,
			<42142 42309 42386 42422 42376 42379>,
			<41900 42075 42153 42187 42142 42146>,
			<41672 41847 41924 41955 41910 41917>,
			<41456 41623 41700 41727 41682 41689>,
			<41251 41397 41476 41502 41457 41462>,
			<41054 41190 41263 41282 41235 41239>,
			<40877 41028 41078 41071 41020 41022>,
			<40702 40882 40902 40862 40808 40809>,
			<40455 40674 40687 40640 40597 40605>,
			<40032 40335 40404 40399 40379 40404>,
			<39636 40001 40130 40177 40177 40212>,
			<39432 39777 39924 39997 40003 40029>,
			<39289 39594 39747 39835 39843 39855>,
			<39135 39412 39565 39673 39680 39684>,
			<38957 39228 39377 39517 39519 39524>,
			<38779 39051 39193 39347 39347 39354>,
			<38609 38883 39011 39128 39128 39138>,
			<38443 38723 38834 38892 38885 38896>,
			<38314 38580 38680 38713 38701 38708>,
			<38219 38455 38548 38575 38566 38573>,
			<38143 38341 38431 38456 38452 38457>,
			<38081 38239 38326 38350 38346 38349>,
			<38029 38144 38231 38255 38250 38252>,
			<37981 38061 38143 38169 38163 38162>,
			<37935 37986 38063 38092 38082 38080>,
			<37892 37922 37989 38021 38009 38005>,
			<37847 37873 37921 37954 37944 37939>,
			<37802 37835 37858 37892 37887 37880>,
			<37753 37799 37807 37831 37824 37814>,
			<37702 37765 37772 37774 37755 37736>,
			<37648 37731 37739 37718 37680 37651>,
			<37588 37694 37699 37658 37599 37557>,
			<37523 37657 37654 37597 37511 37451>,
			<37451 37609 37599 37530 37428 37359>,
			<37372 37537 37529 37460 37355 37293>,
			<37285 37443 37443 37379 37280 37226>,
			<37192 37334 37337 37277 37181 37127>,
			<37093 37203 37208 37154 37061 36995>,
			<36988 37064 37070 37000 36922 36859>,
			<36875 36923 36952 36907 36822 36767>,
			<36756 36821 36899 36872 36796 36760>,
			<36697 36791 36876 36857 36781 36727>,
			<36635 36748 36853 36837 36765 36713>,
			<36548 36679 36810 36799 36730 36671>,
			<36415 36551 36700 36683 36598 36536>,
			<36198 36298 36406 36346 36234 36137>,
			<35813 35843 35904 35841 35728 35659>,
			<35218 35198 35245 35188 35075 35022>,
			<34347 34302 34337 34272 34157 34085>,
			<32781 32835 32900 32904 32819 32823>,
			<29027 29013 29673 29006 29005 29267>;
	};

	qcom,pc-temp-z1-lut {
		qcom,lut-col-legend = <0 10 25 40 50>;
		qcom,lut-row-legend = <10000 9800 9600 9400 9200>,
			<9000 8800 8600 8400 8200>,
			<8000 7800 7600 7400 7200>,
			<7000 6800 6600 6400 6200>,
			<6000 5800 5600 5400 5200>,
			<5000 4800 4600 4400 4200>,
			<4000 3800 3600 3400 3200>,
			<3000 2800 2600 2400 2200>,
			<2000 1800 1600 1400 1200>,
			<1000 900 800 700 600>,
			<500 400 300 200 100>,
			<0>;
		qcom,lut-data = <13418 12845 12159 11930 11930>,
			<13478 12840 12138 11916 11918>,
			<13455 12830 12123 11922 11923>,
			<13427 12816 12116 11922 11924>,
			<13403 12803 12110 11918 11921>,
			<13375 12787 12106 11914 11919>,
			<13364 12773 12101 11911 11919>,
			<13373 12771 12097 11908 11920>,
			<13385 12773 12095 11907 11920>,
			<13388 12774 12092 11904 11917>,
			<13390 12774 12091 11903 11914>,
			<13392 12773 12091 11904 11913>,
			<13385 12768 12091 11904 11914>,
			<13369 12750 12088 11904 11916>,
			<13355 12734 12080 11902 11920>,
			<13338 12730 12077 11901 11923>,
			<13325 12728 12078 11903 11923>,
			<13335 12730 12079 11906 11922>,
			<13364 12742 12082 11908 11922>,
			<13383 12756 12088 11909 11923>,
			<13393 12759 12094 11910 11925>,
			<13401 12761 12099 11914 11930>,
			<13404 12764 12104 11920 11936>,
			<13405 12774 12110 11924 11938>,
			<13405 12786 12117 11926 11936>,
			<13404 12793 12122 11928 11935>,
			<13404 12798 12127 11931 11936>,
			<13408 12803 12131 11933 11937>,
			<13427 12809 12135 11936 11938>,
			<13444 12814 12140 11941 11937>,
			<13445 12816 12145 11946 11938>,
			<13440 12813 12150 11949 11942>,
			<13437 12811 12155 11951 11947>,
			<13440 12816 12159 11954 11948>,
			<13445 12825 12163 11958 11946>,
			<13449 12833 12167 11962 11944>,
			<13463 12840 12173 11967 11948>,
			<13476 12847 12180 11972 11955>,
			<13489 12852 12185 11976 11955>,
			<13501 12856 12188 11979 11947>,
			<13506 12862 12192 11982 11942>,
			<13505 12870 12197 11983 11944>,
			<13506 12877 12201 11985 11949>,
			<13511 12884 12206 11984 11963>,
			<13513 12882 12207 11987 11958>,
			<13513 12879 12206 11988 11957>,
			<13514 12881 12211 11988 11962>,
			<13514 12883 12207 11989 11947>,
			<13517 12886 12212 11991 11944>,
			<13529 12894 12223 11998 11965>,
			<13543 12904 12225 12003 11966>,
			<13567 12917 12238 12010 11961>,
			<13623 12941 12256 12021 11976>,
			<13602 12976 12270 12036 11980>,
			<13602 12976 12270 12036 11980>,
			<13602 12976 12270 12036 11980>;
	};

	qcom,pc-temp-z2-lut {
		qcom,lut-col-legend = <0 10 25 40 50>;
		qcom,lut-row-legend = <10000 9800 9600 9400 9200>,
			<9000 8800 8600 8400 8200>,
			<8000 7800 7600 7400 7200>,
			<7000 6800 6600 6400 6200>,
			<6000 5800 5600 5400 5200>,
			<5000 4800 4600 4400 4200>,
			<4000 3800 3600 3400 3200>,
			<3000 2800 2600 2400 2200>,
			<2000 1800 1600 1400 1200>,
			<1000 900 800 700 600>,
			<500 400 300 200 100>,
			<0>;
		qcom,lut-data = <10556 10878 10836 10752 10302>,
			<10539 10644 10762 10748 10369>,
			<10466 10587 10722 10566 10471>,
			<10409 10562 10726 10538 10490>,
			<10395 10556 10739 10573 10452>,
			<10387 10573 10746 10606 10424>,
			<10385 10598 10758 10627 10447>,
			<10393 10611 10770 10644 10493>,
			<10406 10619 10773 10642 10506>,
			<10418 10624 10779 10613 10484>,
			<10429 10624 10778 10593 10470>,
			<10439 10622 10767 10589 10482>,
			<10449 10625 10753 10582 10495>,
			<10457 10637 10736 10579 10504>,
			<10461 10648 10716 10575 10528>,
			<10463 10653 10711 10572 10546>,
			<10467 10658 10741 10577 10548>,
			<10501 10667 10773 10587 10551>,
			<10580 10689 10764 10595 10554>,
			<10613 10707 10728 10604 10559>,
			<10574 10679 10713 10609 10562>,
			<10515 10602 10734 10586 10525>,
			<10472 10560 10757 10546 10460>,
			<10432 10551 10746 10521 10433>,
			<10412 10544 10700 10487 10393>,
			<10427 10538 10676 10469 10370>,
			<10451 10529 10675 10494 10382>,
			<10457 10525 10676 10536 10401>,
			<10450 10541 10680 10551 10422>,
			<10443 10568 10691 10562 10448>,
			<10447 10584 10702 10570 10471>,
			<10462 10594 10715 10592 10486>,
			<10480 10605 10731 10623 10499>,
			<10508 10621 10746 10630 10514>,
			<10539 10639 10762 10622 10547>,
			<10561 10658 10781 10622 10590>,
			<10578 10678 10817 10671 10679>,
			<10595 10700 10859 10749 10786>,
			<10620 10733 10889 10784 10803>,
			<10644 10772 10917 10809 10777>,
			<10649 10784 10929 10821 10747>,
			<10646 10778 10915 10820 10721>,
			<10645 10775 10902 10827 10702>,
			<10651 10779 10898 10863 10680>,
			<10686 10795 10905 10849 10632>,
			<10745 10814 10939 10722 10689>,
			<10849 10834 10914 10734 10628>,
			<10862 10956 10895 10831 10744>,
			<10897 10972 10923 10783 10689>,
			<11017 10953 11022 10880 10672>,
			<10711 11067 10882 10629 10460>,
			<10517 11079 10949 10528 10361>,
			<10483 11045 10950 10468 10314>,
			<10132 11024 10770 10332 10188>,
			<10132 11024 10770 10332 10188>,
			<10132 11024 10770 10332 10188>;
	};

	qcom,pc-temp-z3-lut {
		qcom,lut-col-legend = <0 10 25 40 50>;
		qcom,lut-row-legend = <10000 9800 9600 9400 9200>,
			<9000 8800 8600 8400 8200>,
			<8000 7800 7600 7400 7200>,
			<7000 6800 6600 6400 6200>,
			<6000 5800 5600 5400 5200>,
			<5000 4800 4600 4400 4200>,
			<4000 3800 3600 3400 3200>,
			<3000 2800 2600 2400 2200>,
			<2000 1800 1600 1400 1200>,
			<1000 900 800 700 600>,
			<500 400 300 200 100>,
			<0>;
		qcom,lut-data = <19369 19344 19336 19298 19320>,
			<19522 19453 19381 19333 19335>,
			<19612 19499 19407 19361 19351>,
			<19661 19527 19407 19365 19354>,
			<19666 19535 19404 19361 19353>,
			<19668 19520 19402 19358 19352>,
			<19668 19502 19398 19358 19352>,
			<19658 19499 19394 19358 19353>,
			<19642 19500 19391 19357 19351>,
			<19632 19501 19384 19350 19343>,
			<19624 19502 19381 19345 19336>,
			<19619 19502 19383 19344 19335>,
			<19621 19500 19385 19343 19335>,
			<19623 19487 19387 19343 19335>,
			<19623 19476 19389 19344 19335>,
			<19617 19476 19390 19345 19335>,
			<19607 19476 19382 19342 19334>,
			<19583 19474 19372 19338 19331>,
			<19540 19461 19366 19336 19330>,
			<19524 19449 19362 19334 19331>,
			<19546 19459 19362 19334 19332>,
			<19577 19489 19380 19343 19340>,
			<19595 19506 19402 19358 19354>,
			<19609 19513 19407 19362 19358>,
			<19617 19516 19409 19363 19357>,
			<19623 19516 19410 19363 19355>,
			<19627 19512 19406 19362 19351>,
			<19627 19508 19402 19360 19347>,
			<19623 19505 19399 19358 19344>,
			<19617 19503 19395 19357 19343>,
			<19612 19500 19391 19356 19342>,
			<19604 19495 19389 19353 19339>,
			<19597 19490 19388 19349 19335>,
			<19589 19486 19386 19346 19332>,
			<19581 19482 19384 19342 19329>,
			<19573 19478 19382 19339 19327>,
			<19564 19474 19379 19339 19326>,
			<19557 19469 19377 19340 19326>,
			<19551 19464 19374 19340 19326>,
			<19547 19459 19372 19337 19325>,
			<19546 19457 19370 19336 19325>,
			<19546 19459 19369 19334 19324>,
			<19546 19460 19369 19333 19325>,
			<19543 19456 19366 19345 19341>,
			<19523 19441 19362 19344 19336>,
			<19498 19438 19359 19335 19333>,
			<19459 19435 19356 19333 19340>,
			<19426 19399 19359 19319 19307>,
			<19327 19396 19337 19320 19312>,
			<19274 19402 19333 19322 19325>,
			<19345 19391 19355 19334 19329>,
			<19262 19379 19335 19337 19331>,
			<19262 19355 19329 19333 19336>,
			<19265 19352 19334 19343 19348>,
			<19265 19352 19334 19343 19348>,
			<19265 19352 19334 19343 19348>;
	};

	qcom,pc-temp-z4-lut {
		qcom,lut-col-legend = <0 10 25 40 50>;
		qcom,lut-row-legend = <10000 9800 9600 9400 9200>,
			<9000 8800 8600 8400 8200>,
			<8000 7800 7600 7400 7200>,
			<7000 6800 6600 6400 6200>,
			<6000 5800 5600 5400 5200>,
			<5000 4800 4600 4400 4200>,
			<4000 3800 3600 3400 3200>,
			<3000 2800 2600 2400 2200>,
			<2000 1800 1600 1400 1200>,
			<1000 900 800 700 600>,
			<500 400 300 200 100>,
			<0>;
		qcom,lut-data = <15529 15162 14912 14803 14766>,
			<15626 15219 14923 14823 14786>,
			<15543 15191 14922 14825 14800>,
			<15426 15089 14901 14822 14801>,
			<15309 15011 14856 14804 14782>,
			<15178 14971 14829 14787 14766>,
			<15097 14940 14818 14779 14763>,
			<15057 14915 14809 14773 14761>,
			<15031 14892 14802 14768 14759>,
			<15014 14882 14795 14762 14753>,
			<15002 14881 14793 14759 14747>,
			<14994 14882 14797 14758 14741>,
			<14989 14881 14801 14757 14736>,
			<14986 14875 14798 14756 14732>,
			<14981 14868 14784 14752 14728>,
			<14973 14858 14769 14747 14725>,
			<14962 14845 14750 14736 14721>,
			<14936 14829 14734 14721 14716>,
			<14893 14801 14732 14714 14712>,
			<14877 14781 14732 14710 14707>,
			<14887 14848 14735 14708 14705>,
			<14908 15026 14809 14747 14734>,
			<14969 15099 14892 14808 14785>,
			<15127 15056 14892 14819 14796>,
			<15224 14993 14863 14809 14790>,
			<15185 14953 14839 14797 14783>,
			<15108 14921 14825 14789 14778>,
			<15056 14899 14815 14782 14772>,
			<15020 14886 14806 14775 14765>,
			<14992 14877 14798 14769 14756>,
			<14972 14871 14791 14762 14749>,
			<14957 14866 14786 14756 14746>,
			<14944 14862 14781 14750 14745>,
			<14934 14858 14776 14744 14740>,
			<14924 14854 14771 14735 14728>,
			<14912 14847 14768 14731 14720>,
			<14896 14834 14769 14740 14729>,
			<14888 14825 14770 14753 14743>,
			<14887 14824 14771 14755 14745>,
			<14888 14825 14773 14753 14741>,
			<14886 14824 14774 14749 14734>,
			<14875 14810 14764 14742 14721>,
			<14866 14800 14756 14737 14710>,
			<14860 14798 14761 14747 14781>,
			<14829 14779 14752 14740 14767>,
			<14816 14749 14727 14716 14715>,
			<14828 14739 14713 14702 14708>,
			<14843 14748 14691 14689 14679>,
			<14931 14736 14688 14664 14652>,
			<14983 14724 14693 14672 14721>,
			<14933 14755 14700 14689 14674>,
			<15030 14769 14716 14689 14686>,
			<15037 14798 14722 14692 14694>,
			<15045 14805 14720 14682 14667>,
			<15045 14805 14720 14682 14667>,
			<15045 14805 14720 14682 14667>;
	};

	qcom,pc-temp-z5-lut {
		qcom,lut-col-legend = <0 10 25 40 50>;
		qcom,lut-row-legend = <10000 9800 9600 9400 9200>,
			<9000 8800 8600 8400 8200>,
			<8000 7800 7600 7400 7200>,
			<7000 6800 6600 6400 6200>,
			<6000 5800 5600 5400 5200>,
			<5000 4800 4600 4400 4200>,
			<4000 3800 3600 3400 3200>,
			<3000 2800 2600 2400 2200>,
			<2000 1800 1600 1400 1200>,
			<1000 900 800 700 600>,
			<500 400 300 200 100>,
			<0>;
		qcom,lut-data = <11767 12188 13585 13041 15181>,
			<13387 14457 15888 15203 16251>,
			<14656 16117 17459 17499 17897>,
			<15713 17507 18154 18119 18673>,
			<16634 18004 18596 18198 19075>,
			<17441 17937 18841 18270 19332>,
			<17884 17849 18826 18550 19569>,
			<18098 18033 18733 18888 19793>,
			<18229 18811 18560 18814 19675>,
			<18267 19353 18116 18039 18519>,
			<18252 19466 17938 17487 17636>,
			<18263 19530 17912 17437 17766>,
			<18862 19398 17939 17440 18092>,
			<19840 18570 18200 17515 18294>,
			<20076 17941 18712 17741 18529>,
			<19768 18354 19027 18013 18755>,
			<19287 19233 19198 18298 18916>,
			<18481 19614 19305 18620 19099>,
			<17274 19494 19254 18962 19476>,
			<16883 19405 19045 19376 20431>,
			<19499 20236 18848 19588 21059>,
			<22648 22060 18626 18787 20075>,
			<23007 22735 18441 17502 18283>,
			<22581 21025 18433 17192 17656>,
			<22068 19082 18519 17200 17543>,
			<21431 19013 18576 17272 17493>,
			<20783 19670 18999 17528 17410>,
			<20668 20461 19493 17967 17328>,
			<21042 21423 19610 18417 17342>,
			<21557 22428 19885 18949 17682>,
			<22064 23052 20252 19383 17987>,
			<22619 23491 20913 19756 18131>,
			<22919 23827 21747 20075 18354>,
			<23062 24128 22487 20180 18756>,
			<23105 24363 23263 20529 19640>,
			<22904 24371 23600 20909 20315>,
			<22444 24003 23564 21246 20293>,
			<22177 23675 23467 21570 20022>,
			<22288 23643 23269 21599 19938>,
			<22520 23638 22799 21030 19804>,
			<22755 23690 22452 20631 19708>,
			<23139 24252 22391 20156 19958>,
			<23233 24518 22275 19852 20243>,
			<22784 23628 21116 21696 22658>,
			<21511 21833 20223 21221 21203>,
			<19372 22181 20066 19469 19698>,
			<16281 22253 20089 19274 24073>,
			<15265 17313 22147 17679 16224>,
			<12887 17681 18232 20323 20159>,
			<11755 18637 17618 19427 21964>,
			<13254 16176 18797 18137 19152>,
			<11383 15141 15501 17765 17546>,
			<11324 13730 14676 16473 17267>,
			<11227 13357 14680 17165 23811>,
			<11227 13357 14680 17165 23811>,
			<11227 13357 14680 17165 23811>;
	};

	qcom,pc-temp-z6-lut {
		qcom,lut-col-legend = <0 10 25 40 50>;
		qcom,lut-row-legend = <10000 9800 9600 9400 9200>,
			<9000 8800 8600 8400 8200>,
			<8000 7800 7600 7400 7200>,
			<7000 6800 6600 6400 6200>,
			<6000 5800 5600 5400 5200>,
			<5000 4800 4600 4400 4200>,
			<4000 3800 3600 3400 3200>,
			<3000 2800 2600 2400 2200>,
			<2000 1800 1600 1400 1200>,
			<1000 900 800 700 600>,
			<500 400 300 200 100>,
			<0>;
		qcom,lut-data = <15577 15094 14778 14676 14669>,
			<15655 15163 14805 14706 14696>,
			<15629 15158 14817 14718 14706>,
			<15589 15121 14809 14718 14706>,
			<15534 15086 14787 14708 14697>,
			<15457 15055 14772 14699 14689>,
			<15404 15029 14764 14695 14688>,
			<15375 15013 14758 14692 14687>,
			<15354 15001 14751 14688 14685>,
			<15340 14995 14744 14682 14678>,
			<15329 14994 14742 14678 14671>,
			<15320 14993 14745 14677 14668>,
			<15312 14990 14748 14676 14666>,
			<15304 14977 14746 14675 14664>,
			<15296 14964 14741 14674 14663>,
			<15288 14957 14734 14672 14662>,
			<15277 14951 14721 14666 14659>,
			<15255 14943 14709 14657 14656>,
			<15222 14928 14707 14654 14653>,
			<15209 14917 14705 14651 14652>,
			<15226 14953 14707 14650 14651>,
			<15258 15049 14751 14673 14670>,
			<15305 15089 14800 14710 14702>,
			<15384 15075 14802 14716 14709>,
			<15428 15055 14792 14713 14705>,
			<15416 15039 14782 14709 14701>,
			<15391 15024 14776 14705 14697>,
			<15372 15015 14770 14701 14692>,
			<15358 15010 14765 14697 14687>,
			<15346 15007 14760 14694 14682>,
			<15337 15003 14756 14691 14678>,
			<15329 15000 14753 14687 14676>,
			<15323 14998 14751 14683 14674>,
			<15318 14996 14749 14679 14670>,
			<15314 14994 14746 14673 14662>,
			<15309 14992 14745 14670 14657>,
			<15303 14986 14744 14674 14661>,
			<15300 14983 14744 14680 14668>,
			<15303 14983 14744 14681 14669>,
			<15309 14984 14745 14680 14664>,
			<15313 14984 14745 14678 14661>,
			<15315 14982 14741 14676 14656>,
			<15318 14981 14738 14673 14652>,
			<15320 14981 14740 14683 14692>,
			<15306 14970 14735 14680 14682>,
			<15294 14957 14723 14666 14660>,
			<15282 14951 14715 14658 14660>,
			<15275 14939 14708 14646 14629>,
			<15269 14935 14696 14635 14619>,
			<15273 14937 14697 14641 14658>,
			<15298 14950 14713 14656 14642>,
			<15309 14956 14713 14659 14649>,
			<15330 14965 14716 14661 14659>,
			<15361 14979 14722 14665 14655>,
			<15361 14979 14722 14665 14655>,
			<15361 14979 14722 14665 14655>;
	};

	qcom,pc-temp-y1-lut {
		qcom,lut-col-legend = <(-10) 0 10 25 40 50>;
		qcom,lut-row-legend = <10000 9800 9600 9400 9200 9000>,
			<8800 8600 8400 8200 8000 7800>,
			<7600 7400 7200 7000 6800 6600>,
			<6400 6200 6000 5800 5600 5400>,
			<5200 5000 4800 4600 4400 4200>,
			<4000 3800 3600 3400 3200 3000>,
			<2800 2600 2400 2200 2000 1800>,
			<1600 1400 1200 1000 900 800>,
			<700 600 500 400 300 200>,
			<100 0>;
		qcom,lut-data = <6777 6269 5908 5499 5358 5336>,
			<6789 6250 5904 5494 5358 5335>,
			<6794 6234 5896 5488 5358 5330>,
			<6794 6222 5886 5483 5357 5324>,
			<6791 6213 5878 5478 5356 5317>,
			<6785 6208 5872 5473 5355 5314>,
			<6772 6209 5869 5468 5354 5311>,
			<6752 6213 5866 5463 5352 5307>,
			<6743 6213 5862 5461 5351 5307>,
			<6739 6200 5854 5459 5351 5312>,
			<6738 6190 5847 5457 5350 5316>,
			<6745 6190 5842 5455 5349 5318>,
			<6758 6189 5838 5453 5348 5320>,
			<6763 6192 5836 5451 5348 5318>,
			<6766 6204 5835 5449 5349 5312>,
			<6770 6214 5835 5448 5351 5306>,
			<6775 6212 5837 5449 5350 5308>,
			<6782 6206 5842 5452 5349 5313>,
			<6784 6204 5843 5453 5349 5316>,
			<6781 6203 5841 5454 5350 5321>,
			<6777 6202 5839 5454 5352 5326>,
			<6775 6204 5840 5455 5354 5328>,
			<6772 6208 5844 5456 5356 5329>,
			<6770 6210 5847 5457 5357 5328>,
			<6767 6201 5850 5460 5359 5325>,
			<6764 6193 5853 5464 5361 5322>,
			<6765 6197 5855 5467 5362 5326>,
			<6768 6210 5857 5471 5364 5334>,
			<6769 6216 5860 5475 5366 5337>,
			<6758 6217 5865 5479 5369 5334>,
			<6743 6218 5870 5484 5372 5331>,
			<6733 6219 5873 5488 5374 5333>,
			<6724 6222 5876 5492 5375 5341>,
			<6720 6225 5878 5496 5377 5346>,
			<6723 6229 5880 5499 5379 5348>,
			<6729 6233 5883 5502 5381 5350>,
			<6739 6233 5886 5505 5384 5351>,
			<6758 6231 5889 5508 5388 5352>,
			<6769 6230 5891 5510 5390 5353>,
			<6749 6233 5893 5513 5390 5354>,
			<6715 6236 5895 5516 5391 5355>,
			<6708 6237 5897 5519 5392 5358>,
			<6715 6233 5901 5522 5394 5362>,
			<6726 6237 5907 5526 5396 5365>,
			<6738 6247 5919 5531 5401 5369>,
			<6741 6235 5926 5539 5407 5370>,
			<6737 6249 5917 5538 5403 5370>,
			<6751 6250 5930 5542 5404 5373>,
			<6739 6235 5938 5543 5405 5360>,
			<6761 6252 5927 5541 5404 5374>,
			<6783 6247 5943 5548 5406 5367>,
			<6787 6250 5957 5559 5413 5369>,
			<6795 6260 5972 5573 5422 5384>,
			<6834 6271 5997 5595 5434 5387>,
			<6834 6271 5997 5595 5434 5387>,
			<6834 6271 5997 5595 5434 5387>;
	};

	qcom,pc-temp-y2-lut {
		qcom,lut-col-legend = <(-10) 0 10 25 40 50>;
		qcom,lut-row-legend = <10000 9800 9600 9400 9200 9000>,
			<8800 8600 8400 8200 8000 7800>,
			<7600 7400 7200 7000 6800 6600>,
			<6400 6200 6000 5800 5600 5400>,
			<5200 5000 4800 4600 4400 4200>,
			<4000 3800 3600 3400 3200 3000>,
			<2800 2600 2400 2200 2000 1800>,
			<1600 1400 1200 1000 900 800>,
			<700 600 500 400 300 200>,
			<100 0>;
		qcom,lut-data = <10182 11184 11459 11606 11314 11440>,
			<10373 11144 11407 11547 11251 11366>,
			<10499 11101 11345 11484 11194 11287>,
			<10572 11061 11282 11424 11147 11212>,
			<10607 11026 11230 11371 11114 11148>,
			<10616 11002 11200 11330 11100 11103>,
			<10572 10987 11190 11294 11105 11074>,
			<10492 10975 11184 11266 11112 11053>,
			<10507 10963 11173 11265 11100 11044>,
			<10783 10948 11149 11283 11066 11052>,
			<11006 10939 11123 11296 11042 11060>,
			<10928 10955 11099 11256 11040 11044>,
			<10754 10996 11077 11190 11039 11015>,
			<10708 11038 11078 11177 11043 11008>,
			<10802 11091 11132 11187 11079 11015>,
			<10899 11131 11189 11204 11106 11017>,
			<10926 11143 11214 11250 11101 11002>,
			<10942 11150 11233 11319 11098 10983>,
			<10952 11157 11252 11368 11128 10989>,
			<10961 11174 11275 11410 11209 11101>,
			<10967 11196 11304 11433 11280 11222>,
			<10722 11226 11339 11428 11310 11275>,
			<10030 11278 11382 11417 11332 11316>,
			<9732 11329 11424 11427 11340 11324>,
			<9735 11390 11474 11494 11369 11275>,
			<9738 11439 11514 11556 11399 11228>,
			<9733 11452 11535 11580 11408 11262>,
			<9716 11460 11555 11597 11417 11356>,
			<9702 11465 11567 11600 11430 11400>,
			<9693 11461 11581 11576 11450 11424>,
			<9685 11437 11594 11556 11474 11443>,
			<9679 11376 11606 11545 11499 11482>,
			<9674 11261 11625 11530 11528 11584>,
			<9670 11142 11628 11528 11549 11621>,
			<9667 11003 11588 11544 11564 11528>,
			<9664 10877 11533 11558 11570 11428>,
			<9662 10872 11500 11560 11546 11445>,
			<9660 11010 11472 11560 11487 11518>,
			<9658 11071 11440 11560 11463 11544>,
			<9657 10989 11404 11562 11493 11454>,
			<9655 10873 11362 11562 11521 11351>,
			<9654 10778 11312 11544 11498 11346>,
			<9654 10693 11246 11519 11444 11371>,
			<9653 10371 11156 11508 11405 11361>,
			<9653 9747 11047 11474 11346 11301>,
			<9653 9694 10969 11419 11251 11129>,
			<9653 9700 10951 11416 11191 11076>,
			<9653 9695 10928 11351 11174 11220>,
			<9652 9687 10882 11344 11283 11075>,
			<9652 9680 10810 11341 11202 11085>,
			<9652 9675 10771 11247 11141 10956>,
			<9652 9668 10663 11173 11080 10920>,
			<9651 9661 10516 11021 11011 10857>,
			<9650 9656 10345 10931 10807 10625>,
			<9650 9656 10345 10931 10807 10625>,
			<9650 9656 10345 10931 10807 10625>;
	};

	qcom,pc-temp-y3-lut {
		qcom,lut-col-legend = <(-10) 0 10 25 40 50>;
		qcom,lut-row-legend = <10000 9800 9600 9400 9200 9000>,
			<8800 8600 8400 8200 8000 7800>,
			<7600 7400 7200 7000 6800 6600>,
			<6400 6200 6000 5800 5600 5400>,
			<5200 5000 4800 4600 4400 4200>,
			<4000 3800 3600 3400 3200 3000>,
			<2800 2600 2400 2200 2000 1800>,
			<1600 1400 1200 1000 900 800>,
			<700 600 500 400 300 200>,
			<100 0>;
		qcom,lut-data = <13474 13341 13299 13288 13272 13279>,
			<13473 13346 13303 13285 13273 13277>,
			<13475 13350 13307 13282 13274 13276>,
			<13479 13354 13311 13280 13275 13275>,
			<13484 13357 13314 13278 13276 13274>,
			<13491 13361 13315 13278 13276 13275>,
			<13503 13364 13316 13279 13276 13275>,
			<13515 13366 13316 13282 13276 13277>,
			<13513 13369 13316 13284 13276 13277>,
			<13474 13371 13319 13286 13277 13277>,
			<13438 13374 13322 13287 13277 13277>,
			<13429 13378 13325 13288 13278 13277>,
			<13424 13383 13329 13289 13278 13277>,
			<13418 13382 13329 13289 13279 13277>,
			<13411 13369 13328 13289 13281 13277>,
			<13405 13355 13325 13289 13282 13277>,
			<13401 13351 13324 13292 13282 13278>,
			<13399 13348 13323 13297 13282 13281>,
			<13396 13345 13321 13298 13283 13283>,
			<13390 13339 13317 13298 13286 13285>,
			<13381 13334 13312 13297 13289 13286>,
			<13355 13330 13310 13294 13285 13283>,
			<13307 13327 13308 13288 13277 13276>,
			<13285 13325 13306 13284 13274 13274>,
			<13283 13320 13302 13281 13275 13274>,
			<13281 13315 13299 13279 13275 13273>,
			<13283 13315 13299 13279 13275 13273>,
			<13291 13313 13299 13279 13275 13274>,
			<13302 13312 13300 13279 13274 13274>,
			<13315 13307 13299 13282 13274 13273>,
			<13331 13300 13299 13283 13274 13273>,
			<13349 13298 13298 13283 13274 13273>,
			<13370 13297 13296 13283 13275 13274>,
			<13396 13296 13295 13283 13276 13274>,
			<13432 13299 13297 13282 13275 13273>,
			<13478 13304 13300 13282 13275 13272>,
			<13532 13311 13302 13281 13275 13272>,
			<13601 13324 13303 13280 13275 13273>,
			<13685 13335 13305 13280 13274 13273>,
			<13793 13339 13306 13281 13275 13274>,
			<13929 13343 13307 13281 13275 13274>,
			<14085 13348 13309 13281 13275 13274>,
			<14274 13355 13310 13280 13274 13273>,
			<14471 13364 13312 13281 13274 13274>,
			<14672 13380 13316 13284 13275 13275>,
			<14852 13416 13322 13285 13277 13277>,
			<14786 13431 13322 13287 13280 13282>,
			<14856 13458 13330 13291 13284 13276>,
			<14963 13502 13338 13295 13286 13283>,
			<15072 13548 13346 13297 13285 13281>,
			<15187 13594 13349 13292 13281 13280>,
			<15320 13649 13355 13295 13283 13284>,
			<15655 13790 13372 13301 13289 13283>,
			<16521 14091 13412 13306 13291 13289>,
			<16521 14091 13412 13306 13291 13289>,
			<16521 14091 13412 13306 13291 13289>;
	};

	qcom,pc-temp-y4-lut {
		qcom,lut-col-legend = <(-10) 0 10 25 40 50>;
		qcom,lut-row-legend = <10000 9800 9600 9400 9200 9000>,
			<8800 8600 8400 8200 8000 7800>,
			<7600 7400 7200 7000 6800 6600>,
			<6400 6200 6000 5800 5600 5400>,
			<5200 5000 4800 4600 4400 4200>,
			<4000 3800 3600 3400 3200 3000>,
			<2800 2600 2400 2200 2000 1800>,
			<1600 1400 1200 1000 900 800>,
			<700 600 500 400 300 200>,
			<100 0>;
		qcom,lut-data = <17018 16672 16573 16477 16482 16467>,
			<17058 16694 16574 16481 16476 16466>,
			<17121 16716 16576 16486 16472 16465>,
			<17189 16738 16579 16492 16470 16465>,
			<17247 16756 16582 16497 16469 16465>,
			<17277 16769 16585 16499 16469 16466>,
			<17280 16776 16589 16500 16470 16467>,
			<17281 16782 16592 16500 16473 16468>,
			<17308 16789 16597 16501 16475 16469>,
			<17493 16798 16606 16504 16477 16468>,
			<17693 16813 16617 16508 16480 16468>,
			<17809 16889 16634 16515 16483 16470>,
			<17899 17015 16657 16524 16487 16475>,
			<17877 17046 16677 16532 16490 16479>,
			<17399 16995 16694 16538 16494 16484>,
			<16966 16934 16713 16547 16499 16489>,
			<16960 16899 16746 16568 16507 16494>,
			<16991 16870 16785 16598 16521 16499>,
			<16999 16834 16793 16627 16539 16509>,
			<16935 16784 16742 16659 16571 16536>,
			<16860 16731 16674 16677 16592 16557>,
			<16834 16683 16618 16624 16566 16538>,
			<16818 16636 16564 16529 16506 16493>,
			<16807 16612 16539 16495 16480 16474>,
			<16797 16603 16530 16485 16472 16471>,
			<16790 16596 16525 16481 16469 16470>,
			<16790 16588 16523 16481 16469 16469>,
			<16794 16579 16522 16483 16471 16468>,
			<16798 16574 16521 16485 16473 16468>,
			<16805 16573 16523 16489 16477 16472>,
			<16814 16575 16525 16495 16482 16478>,
			<16823 16581 16524 16501 16490 16485>,
			<16836 16593 16521 16507 16501 16494>,
			<16848 16607 16519 16508 16504 16497>,
			<16859 16623 16523 16503 16499 16489>,
			<16869 16639 16528 16496 16491 16478>,
			<16881 16654 16532 16487 16480 16471>,
			<16892 16671 16537 16477 16465 16465>,
			<16906 16687 16541 16475 16460 16463>,
			<16924 16704 16546 16477 16466 16472>,
			<16947 16720 16551 16481 16473 16483>,
			<16977 16726 16561 16485 16475 16480>,
			<17019 16727 16579 16487 16476 16464>,
			<17081 16741 16595 16482 16467 16449>,
			<17181 16795 16614 16483 16457 16442>,
			<17313 16884 16660 16503 16479 16500>,
			<17268 16902 16663 16515 16493 16498>,
			<17319 16965 16710 16539 16528 16536>,
			<17415 17060 16777 16579 16562 16579>,
			<17519 17173 16837 16588 16553 16527>,
			<17596 17249 16824 16542 16486 16462>,
			<17583 17251 16795 16548 16489 16493>,
			<17686 17333 16846 16585 16502 16493>,
			<18363 17540 16946 16649 16539 16476>,
			<18363 17540 16946 16649 16539 16476>,
			<18363 17540 16946 16649 16539 16476>;
	};

	qcom,pc-temp-y5-lut {
		qcom,lut-col-legend = <(-10) 0 10 25 40 50>;
		qcom,lut-row-legend = <10000 9800 9600 9400 9200 9000>,
			<8800 8600 8400 8200 8000 7800>,
			<7600 7400 7200 7000 6800 6600>,
			<6400 6200 6000 5800 5600 5400>,
			<5200 5000 4800 4600 4400 4200>,
			<4000 3800 3600 3400 3200 3000>,
			<2800 2600 2400 2200 2000 1800>,
			<1600 1400 1200 1000 900 800>,
			<700 600 500 400 300 200>,
			<100 0>;
		qcom,lut-data = <14603 15138 13485 17459 13759 18024>,
			<14038 15600 14507 16317 14432 17222>,
			<13822 15956 15189 15208 14842 16520>,
			<13875 16209 15597 14257 15055 15974>,
			<14116 16362 15796 13590 15135 15638>,
			<14463 16416 15850 13335 15147 15570>,
			<15139 16274 15607 13565 14951 15912>,
			<15962 16001 15186 13945 14565 16405>,
			<15892 15872 15082 14104 14305 16458>,
			<13817 15842 15049 14365 14107 16000>,
			<12131 15779 14946 14467 13988 15499>,
			<13385 15116 14657 14304 13942 14978>,
			<16065 13952 14291 14093 13911 14298>,
			<16814 13711 14206 13865 13933 13943>,
			<15896 14663 14305 13568 14129 13726>,
			<15062 15663 14477 13404 14281 13615>,
			<15314 16024 14840 13679 14174 13876>,
			<16015 16256 15468 14322 13959 14516>,
			<16294 16431 16070 15039 14028 15035>,
			<16314 16597 16651 15988 15157 15577>,
			<16324 16697 17213 16859 16108 15930>,
			<15408 16684 17790 17568 15879 15801>,
			<12771 16634 18341 18133 15338 15471>,
			<11445 16579 18434 18028 15254 15390>,
			<11221 16137 17430 16632 16117 15855>,
			<11105 15682 16409 15581 16887 16342>,
			<11100 15624 16412 15577 16809 16434>,
			<11162 15514 16705 15661 16526 16433>,
			<11231 15327 16834 15963 16287 16350>,
			<11317 14619 16916 17230 16013 16089>,
			<11415 13787 17004 18248 15822 15854>,
			<11482 13413 16845 18427 16027 16119>,
			<11534 13101 16353 18526 16682 16961>,
			<11584 12980 16185 18585 17357 17364>,
			<11640 13262 17033 18902 18221 17331>,
			<11694 13702 18049 19120 18873 17290>,
			<11741 14293 18351 18568 18909 17775>,
			<11787 15803 18607 17558 18763 19224>,
			<11809 16633 18631 17237 18527 19870>,
			<11792 16627 18309 17305 17962 18607>,
			<11763 16612 17805 17339 17236 16943>,
			<11761 16573 17162 16635 16514 16233>,
			<11783 16402 16331 15730 15841 15722>,
			<11757 15388 15968 16323 16381 16751>,
			<11610 12696 15790 17042 17073 18357>,
			<11577 12087 15390 16273 15634 15968>,
			<11775 12448 15256 16204 15638 17854>,
			<12112 12687 15467 16411 16063 13275>,
			<12339 12913 15508 16413 16164 15278>,
			<12531 13140 15678 16905 15783 14815>,
			<12698 13362 15869 16153 16259 18296>,
			<12421 12917 15814 16859 16388 17859>,
			<11473 12176 15204 17251 18395 15080>,
			<10230 11369 14664 16843 17886 20463>,
			<10230 11369 14664 16843 17886 20463>,
			<10230 11369 14664 16843 17886 20463>;
	};

	qcom,pc-temp-y6-lut {
		qcom,lut-col-legend = <(-10) 0 10 25 40 50>;
		qcom,lut-row-legend = <10000 9800 9600 9400 9200 9000>,
			<8800 8600 8400 8200 8000 7800>,
			<7600 7400 7200 7000 6800 6600>,
			<6400 6200 6000 5800 5600 5400>,
			<5200 5000 4800 4600 4400 4200>,
			<4000 3800 3600 3400 3200 3000>,
			<2800 2600 2400 2200 2000 1800>,
			<1600 1400 1200 1000 900 800>,
			<700 600 500 400 300 200>,
			<100 0>;
		qcom,lut-data = <5995 5376 5178 5062 5036 5037>,
			<5987 5378 5180 5061 5035 5034>,
			<5979 5379 5181 5059 5035 5032>,
			<5971 5379 5181 5059 5035 5031>,
			<5963 5379 5180 5058 5036 5030>,
			<5957 5379 5180 5058 5036 5030>,
			<5949 5377 5179 5059 5037 5031>,
			<5942 5375 5177 5061 5037 5032>,
			<5942 5375 5177 5062 5038 5033>,
			<5955 5375 5179 5064 5039 5033>,
			<5973 5377 5183 5066 5040 5034>,
			<5994 5396 5188 5069 5041 5034>,
			<6015 5431 5196 5072 5043 5036>,
			<6008 5439 5201 5074 5044 5037>,
			<5877 5414 5203 5075 5046 5038>,
			<5758 5387 5206 5078 5049 5039>,
			<5757 5374 5214 5086 5052 5041>,
			<5767 5366 5225 5098 5056 5045>,
			<5770 5354 5226 5107 5061 5049>,
			<5756 5336 5209 5116 5072 5059>,
			<5735 5318 5185 5120 5080 5066>,
			<5717 5302 5168 5103 5070 5059>,
			<5699 5289 5152 5072 5046 5041>,
			<5692 5282 5143 5059 5037 5033>,
			<5701 5278 5139 5054 5036 5031>,
			<5715 5276 5136 5052 5035 5030>,
			<5732 5276 5136 5052 5035 5030>,
			<5756 5277 5138 5053 5036 5031>,
			<5784 5278 5139 5054 5036 5032>,
			<5813 5279 5141 5057 5037 5032>,
			<5847 5280 5143 5060 5039 5033>,
			<5885 5282 5143 5063 5042 5036>,
			<5927 5290 5142 5065 5045 5040>,
			<5974 5300 5142 5065 5047 5041>,
			<6027 5312 5146 5064 5045 5038>,
			<6087 5327 5152 5062 5043 5034>,
			<6155 5347 5156 5060 5040 5033>,
			<6231 5372 5160 5056 5035 5031>,
			<6318 5399 5164 5056 5034 5031>,
			<6419 5425 5169 5058 5036 5034>,
			<6535 5454 5174 5059 5039 5038>,
			<6669 5487 5182 5061 5039 5037>,
			<6826 5528 5192 5062 5040 5032>,
			<6997 5578 5204 5062 5038 5029>,
			<7180 5645 5221 5064 5035 5028>,
			<7358 5749 5248 5072 5044 5047>,
			<7301 5765 5249 5078 5050 5050>,
			<7366 5820 5275 5088 5062 5057>,
			<7473 5900 5307 5102 5074 5073>,
			<7586 5984 5339 5107 5071 5057>,
			<7701 6063 5347 5090 5049 5038>,
			<7802 6145 5359 5096 5052 5050>,
			<8106 6336 5419 5114 5062 5051>,
			<9012 6660 5528 5140 5075 5052>,
			<9012 6660 5528 5140 5075 5052>,
			<9012 6660 5528 5140 5075 5052>;
	};

};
